AUTOSAR XML (schema 00048)
package /VehicleProject
  system System
package /NM
  nm config NmConfig: can-nm-cluster-coupling=coupled-cluster=[TC37X_VCU_CAN00_CAN, TC37X_VCU_CAN01_CAN, TC37X_VCU_CAN03_CAN]
    can nm cluster TC37X_VCU_CAN00_CAN: communication-cluster=TC37X_VCU_CAN00, nm-channel-id=0, nm-cbv-position=1, nm-msg-cycle-time=0.5, nm-network-timeout=2, nm-repeat-message-time=1.5, nm-user-data-length=6, nm-wait-bus-sleep-time=2
      can nm node GWM: nm-if-ecu=GWM_CAN, nm-node-id=28, rx-nm-pdu=VCU_Tx_51Ch_NM_oTC37X_VCU_CAN00, tx-nm-pdu=VCU_Rx_500h_NM_oTC37X_VCU_CAN00, nm-msg-cycle-offset=0, nm-msg-reduced-time=0.32, nm-range-config={lower-can-id=1024, upper-can-id=1151}
      can nm node Tester: nm-if-ecu=Tester_CAN, nm-node-id=28, nm-passive-mode-enabled=true, nm-msg-cycle-offset=0, nm-msg-reduced-time=0.32, nm-range-config={lower-can-id=1024, upper-can-id=1151}
      can nm node VCU: controller=CT_TC37X_VCU_CAN00, nm-if-ecu=VCU_CAN, nm-node-id=28, rx-nm-pdu=VCU_Rx_500h_NM_oTC37X_VCU_CAN00, tx-nm-pdu=VCU_Tx_51Ch_NM_oTC37X_VCU_CAN00, nm-msg-cycle-offset=0, nm-msg-reduced-time=0.32, nm-range-config={lower-can-id=1024, upper-can-id=1151}
    can nm cluster TC37X_VCU_CAN01_CAN: communication-cluster=TC37X_VCU_CAN01, nm-channel-id=1, nm-cbv-position=1, nm-msg-cycle-time=0.5, nm-network-timeout=2, nm-repeat-message-time=1.5, nm-user-data-length=6, nm-wait-bus-sleep-time=2
      can nm node GWM: nm-if-ecu=GWM_CAN, nm-node-id=28, rx-nm-pdu=VCU_Tx_51Ch_NM_oTC37X_VCU_CAN01, tx-nm-pdu=VCU_Rx_500h_NM_oTC37X_VCU_CAN01, nm-msg-cycle-offset=0, nm-msg-reduced-time=0.32, nm-range-config={lower-can-id=1024, upper-can-id=1151}
      can nm node Tester: nm-if-ecu=Tester_CAN, nm-node-id=28, nm-passive-mode-enabled=true, nm-msg-cycle-offset=0, nm-msg-reduced-time=0.32, nm-range-config={lower-can-id=1024, upper-can-id=1151}
      can nm node VCU: controller=CT_TC37X_VCU_CAN01, nm-if-ecu=VCU_CAN, nm-node-id=28, rx-nm-pdu=VCU_Rx_500h_NM_oTC37X_VCU_CAN01, tx-nm-pdu=VCU_Tx_51Ch_NM_oTC37X_VCU_CAN01, nm-msg-cycle-offset=0, nm-msg-reduced-time=0.32, nm-range-config={lower-can-id=1024, upper-can-id=1151}
    can nm cluster TC37X_VCU_CAN03_CAN: communication-cluster=TC37X_VCU_CAN03, nm-channel-id=2, nm-cbv-position=1, nm-msg-cycle-time=0.5, nm-network-timeout=2, nm-repeat-message-time=1.5, nm-user-data-length=6, nm-wait-bus-sleep-time=2
      can nm node GWM: nm-if-ecu=GWM_CAN, nm-node-id=28, rx-nm-pdu=VCU_Tx_51Ch_NM_oTC37X_VCU_CAN03, tx-nm-pdu=VCU_Rx_500h_NM_oTC37X_VCU_CAN03, nm-msg-cycle-offset=0, nm-msg-reduced-time=0.32, nm-range-config={lower-can-id=1024, upper-can-id=1151}
      can nm node Tester: nm-if-ecu=Tester_CAN, nm-node-id=28, nm-passive-mode-enabled=true, nm-msg-cycle-offset=0, nm-msg-reduced-time=0.32, nm-range-config={lower-can-id=1024, upper-can-id=1151}
      can nm node VCU: controller=CT_TC37X_VCU_CAN03, nm-if-ecu=VCU_CAN, nm-node-id=28, rx-nm-pdu=VCU_Rx_500h_NM_oTC37X_VCU_CAN03, tx-nm-pdu=VCU_Tx_51Ch_NM_oTC37X_VCU_CAN03, nm-msg-cycle-offset=0, nm-msg-reduced-time=0.32, nm-range-config={lower-can-id=1024, upper-can-id=1151}
    nm-if-ecus:
      nm ecu GWM_CAN: nm-node-id-enabled=true, nm-user-data-enabled=true
      nm ecu Tester_CAN: nm-node-id-enabled=true, nm-passive-mode-enabled=true, nm-user-data-enabled=true
      nm ecu VCU_CAN: ecu-instance=VCU, nm-node-id-enabled=true, nm-user-data-enabled=true
package /TP
  can tp config TC37X_VCU_CAN00_CAN: communication-cluster=TC37X_VCU_CAN00, can-tp-ecu{cycle-time-main-function=0.005, ecu-instance=VCU}
    can tp channel TPCH: channel-id=0, channel-mode=FULL-DUPLEX-MODE
    can-tp-connection addressing-format=STANDARD, can-tp-channel=TPCH, data-pdu=Vcu_Uds_Func_Request_Tp_oTC37X_VCU_CAN00, receiver=TN_VCU, ta-type=FUNCTIONAL, tp-sdu=Vcu_Uds_Func_Request_oTC37X_VCU_CAN00, transmitter=TN_Tester:
      ident Vcu_Uds_Func_Request_oTN_Tester
    can-tp-connection addressing-format=STANDARD, can-tp-channel=TPCH, data-pdu=Vcu_Uds_Phy_Request_Tp_oTC37X_VCU_CAN00, flow-control-pdu=Vcu_Uds_Response_Tp_oTC37X_VCU_CAN00, receiver=TN_VCU, ta-type=PHYSICAL, tp-sdu=Vcu_Uds_Phy_Request_oTC37X_VCU_CAN00, transmitter=TN_Tester:
      ident Vcu_Uds_Phy_Request_oTN_VCU
    can-tp-connection addressing-format=STANDARD, can-tp-channel=TPCH, data-pdu=Vcu_Uds_Response_Tp_oTC37X_VCU_CAN00, flow-control-pdu=Vcu_Uds_Phy_Request_Tp_oTC37X_VCU_CAN00, receiver=TN_Tester, ta-type=PHYSICAL, tp-sdu=Vcu_Uds_Response_oTC37X_VCU_CAN00, transmitter=TN_VCU:
      ident Vcu_Uds_Response_oTN_VCU
    can tp node TN_Tester
    can tp node TN_VCU: connector=CN_TC37X_VCU_CAN00
  lin tp config LIN00: communication-cluster=LIN00
    8 x tp address:
      TA_0x005B: tp-address=91
      TA_0x0062: tp-address=98
      TA_0x0063: tp-address=99
      TA_0x0064: tp-address=100
      TA_0x0065: tp-address=101
      TA_0x0074: tp-address=116
      TA_0x0075: tp-address=117
      TA_0x007E: tp-address=126
    tp-connections:
      data-pdu=MasterReq_Tp_oLIN00, lin-tp-n-sdu=MasterReq_oLIN00, multicast=TA_0x007E, receiver=[TN_0x005B_HVCH, TN_0x0062_ERV, TN_0x0063_EXV_1, TN_0x0064_EXV_2, TN_0x0065_SVA, TN_0x0074_PMP_1, TN_0x0075_PMP_2], transmitter=TN_Master
      data-pdu=SlaveResp_Tp_oLIN00, flow-control=MasterReq_Tp_oLIN00, lin-tp-n-sdu=SlaveResp_HVCH_oLIN00, receiver=TN_Master, transmitter=TN_0x005B_HVCH
      data-pdu=SlaveResp_Tp_oLIN00, flow-control=MasterReq_Tp_oLIN00, lin-tp-n-sdu=SlaveResp_ERV_oLIN00, receiver=TN_Master, transmitter=TN_0x0062_ERV
      data-pdu=SlaveResp_Tp_oLIN00, flow-control=MasterReq_Tp_oLIN00, lin-tp-n-sdu=SlaveResp_EXV_1_oLIN00, receiver=TN_Master, transmitter=TN_0x0063_EXV_1
      data-pdu=SlaveResp_Tp_oLIN00, flow-control=MasterReq_Tp_oLIN00, lin-tp-n-sdu=SlaveResp_EXV_2_oLIN00, receiver=TN_Master, transmitter=TN_0x0064_EXV_2
      data-pdu=SlaveResp_Tp_oLIN00, flow-control=MasterReq_Tp_oLIN00, lin-tp-n-sdu=SlaveResp_SVA_oLIN00, receiver=TN_Master, transmitter=TN_0x0065_SVA
      data-pdu=SlaveResp_Tp_oLIN00, flow-control=MasterReq_Tp_oLIN00, lin-tp-n-sdu=SlaveResp_PMP_1_oLIN00, receiver=TN_Master, transmitter=TN_0x0074_PMP_1
      data-pdu=SlaveResp_Tp_oLIN00, flow-control=MasterReq_Tp_oLIN00, lin-tp-n-sdu=SlaveResp_PMP_2_oLIN00, receiver=TN_Master, transmitter=TN_0x0075_PMP_2
      data-pdu=MasterReq_Tp_oLIN00, flow-control=SlaveResp_Tp_oLIN00, lin-tp-n-sdu=MasterReq_HVCH_oLIN00, receiver=TN_0x005B_HVCH, transmitter=TN_Master
      data-pdu=MasterReq_Tp_oLIN00, flow-control=SlaveResp_Tp_oLIN00, lin-tp-n-sdu=MasterReq_ERV_oLIN00, receiver=TN_0x0062_ERV, transmitter=TN_Master
      data-pdu=MasterReq_Tp_oLIN00, flow-control=SlaveResp_Tp_oLIN00, lin-tp-n-sdu=MasterReq_EXV_1_oLIN00, receiver=TN_0x0063_EXV_1, transmitter=TN_Master
      data-pdu=MasterReq_Tp_oLIN00, flow-control=SlaveResp_Tp_oLIN00, lin-tp-n-sdu=MasterReq_EXV_2_oLIN00, receiver=TN_0x0064_EXV_2, transmitter=TN_Master
      data-pdu=MasterReq_Tp_oLIN00, flow-control=SlaveResp_Tp_oLIN00, lin-tp-n-sdu=MasterReq_SVA_oLIN00, receiver=TN_0x0065_SVA, transmitter=TN_Master
      data-pdu=MasterReq_Tp_oLIN00, flow-control=SlaveResp_Tp_oLIN00, lin-tp-n-sdu=MasterReq_PMP_1_oLIN00, receiver=TN_0x0074_PMP_1, transmitter=TN_Master
      data-pdu=MasterReq_Tp_oLIN00, flow-control=SlaveResp_Tp_oLIN00, lin-tp-n-sdu=MasterReq_PMP_2_oLIN00, receiver=TN_0x0075_PMP_2, transmitter=TN_Master
    8 x lin tp node:
      TN_0x005B_HVCH: tp-address=TA_0x005B
      TN_0x0062_ERV: tp-address=TA_0x0062
      TN_0x0063_EXV_1: tp-address=TA_0x0063
      TN_0x0064_EXV_2: tp-address=TA_0x0064
      TN_0x0065_SVA: tp-address=TA_0x0065
      TN_0x0074_PMP_1: tp-address=TA_0x0074
      TN_0x0075_PMP_2: tp-address=TA_0x0075
      TN_Master: connector=CN_LIN00
package /Cluster
  4 x can cluster, all with baudrate=500000, protocol-name=CAN:
    KAMA_FP_EPT_0303
      can physical channel CHNL: comm-connectors=CN_KAMA_FP_EPT_0303
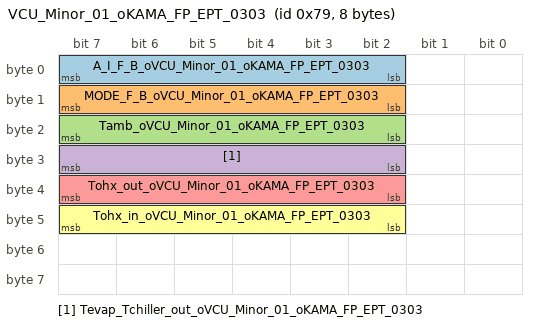
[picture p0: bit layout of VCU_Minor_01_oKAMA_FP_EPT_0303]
        frame VCU_Minor_01_oKAMA_FP_EPT_0303: id 0x79, from VCU, frame-length=8, can-addressing-mode=STANDARD
          pdu VCU_Minor_01_oKAMA_FP_EPT_0303: length=8, minimum-delay=0, transmission-mode-false-timing=cyclic-timing={time-offset=0, time-period=0.02}, transmission-mode-true-timing=cyclic-timing={time-offset=0, time-period=0.02}, unused-bit-pattern=0
            signal A_I_F_B_oVCU_Minor_01_oKAMA_FP_EPT_0303: start 7, 6 bit, big-endian, i-signal-type=PRIMITIVE, init-value=0, base-type=uint8, compu-method=CM_A_I_F_B, data-constr=DC_A_I_F_B, unit=U_V, transfer-property=PENDING
            signal MODE_F_B_oVCU_Minor_01_oKAMA_FP_EPT_0303: start 15, 6 bit, big-endian, i-signal-type=PRIMITIVE, init-value=0, base-type=uint8, compu-method=CM_MODE_F_B, data-constr=DC_MODE_F_B, unit=U_V, transfer-property=PENDING
            signal Tamb_oVCU_Minor_01_oKAMA_FP_EPT_0303: start 23, 6 bit, big-endian, i-signal-type=PRIMITIVE, init-value=0, base-type=uint8, compu-method=CM_Tamb, data-constr=DC_Tamb, unit=U_V, transfer-property=PENDING
            signal Tevap_Tchiller_out_oVCU_Minor_01_oKAMA_FP_EPT_0303: start 31, 6 bit, big-endian, i-signal-type=PRIMITIVE, init-value=0, base-type=uint8, compu-method=CM_Tevap_Tchiller_out, data-constr=DC_Tevap_Tchiller_out, unit=U_V, transfer-property=PENDING
            signal Tohx_out_oVCU_Minor_01_oKAMA_FP_EPT_0303: start 39, 6 bit, big-endian, i-signal-type=PRIMITIVE, init-value=0, base-type=uint8, compu-method=CM_Tohx_out, data-constr=DC_Tohx_out, unit=U_V, transfer-property=PENDING
            signal Tohx_in_oVCU_Minor_01_oKAMA_FP_EPT_0303: start 47, 6 bit, big-endian, i-signal-type=PRIMITIVE, init-value=0, base-type=uint8, compu-method=CM_Tohx_in, data-constr=DC_Tohx_in, unit=U_V, transfer-property=PENDING
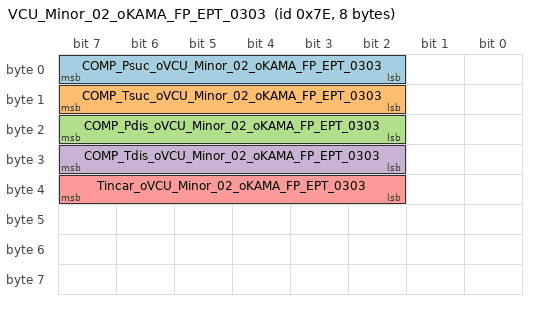
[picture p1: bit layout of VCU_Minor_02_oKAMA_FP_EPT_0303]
        frame VCU_Minor_02_oKAMA_FP_EPT_0303: id 0x7E, from VCU, frame-length=8, can-addressing-mode=STANDARD
          pdu VCU_Minor_02_oKAMA_FP_EPT_0303: length=8, minimum-delay=0, transmission-mode-false-timing=cyclic-timing={time-offset=0, time-period=0.02}, transmission-mode-true-timing=cyclic-timing={time-offset=0, time-period=0.02}, unused-bit-pattern=0
            signal COMP_Psuc_oVCU_Minor_02_oKAMA_FP_EPT_0303: start 7, 6 bit, big-endian, i-signal-type=PRIMITIVE, init-value=0, base-type=uint8, compu-method=CM_COMP_Psuc, data-constr=DC_COMP_Psuc, unit=U_V, transfer-property=PENDING
            signal COMP_Tsuc_oVCU_Minor_02_oKAMA_FP_EPT_0303: start 15, 6 bit, big-endian, i-signal-type=PRIMITIVE, init-value=0, base-type=uint8, compu-method=CM_COMP_Tsuc, data-constr=DC_COMP_Tsuc, unit=U_V, transfer-property=PENDING
            signal COMP_Pdis_oVCU_Minor_02_oKAMA_FP_EPT_0303: start 23, 6 bit, big-endian, i-signal-type=PRIMITIVE, init-value=0, base-type=uint8, compu-method=CM_COMP_Pdis, data-constr=DC_COMP_Pdis, unit=U_V, transfer-property=PENDING
            signal COMP_Tdis_oVCU_Minor_02_oKAMA_FP_EPT_0303: start 31, 6 bit, big-endian, i-signal-type=PRIMITIVE, init-value=0, base-type=uint8, compu-method=CM_COMP_Tdis, data-constr=DC_COMP_Tdis, unit=U_V, transfer-property=PENDING
            signal Tincar_oVCU_Minor_02_oKAMA_FP_EPT_0303: start 39, 6 bit, big-endian, i-signal-type=PRIMITIVE, init-value=0, base-type=uint8, compu-method=CM_Tincar, data-constr=DC_Tincar, unit=U_V, transfer-property=PENDING
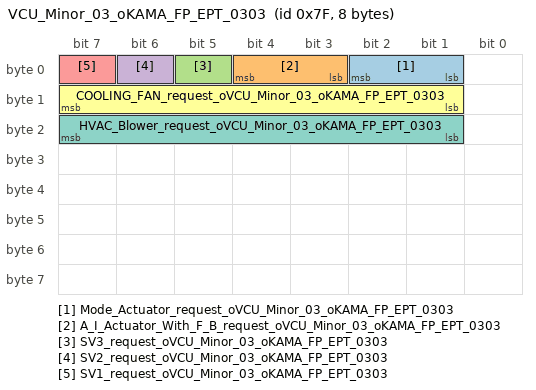
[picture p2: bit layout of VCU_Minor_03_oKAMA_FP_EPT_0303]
        frame VCU_Minor_03_oKAMA_FP_EPT_0303: id 0x7F, to VCU, frame-length=8, can-addressing-mode=STANDARD
          pdu VCU_Minor_03_oKAMA_FP_EPT_0303: length=8, minimum-delay=0, transmission-mode-false-timing=cyclic-timing={time-offset=0, time-period=0.02}, transmission-mode-true-timing=cyclic-timing={time-offset=0, time-period=0.02}, unused-bit-pattern=0
            signal Mode_Actuator_request_oVCU_Minor_03_oKAMA_FP_EPT_0303: start 2, 2 bit, big-endian, i-signal-type=PRIMITIVE, init-value=0, base-type=uint8, compu-method=CM_Mode_Actuator_request, data-constr=DC_Mode_Actuator_request, transfer-property=PENDING, to VCU
            signal A_I_Actuator_With_F_B_request_oVCU_Minor_03_oKAMA_FP_EPT_0303: start 4, 2 bit, big-endian, i-signal-type=PRIMITIVE, init-value=0, base-type=uint8, compu-method=CM_A_I_Actuator_With_F_B_request, data-constr=DC_A_I_Actuator_With_F_B_request, transfer-property=PENDING, to VCU
            signal SV3_request_oVCU_Minor_03_oKAMA_FP_EPT_0303: start 5, 1 bit, big-endian, i-signal-type=PRIMITIVE, init-value=0, base-type=boolean, compu-method=CM_SV3_request, data-constr=DC_SV3_request, transfer-property=PENDING, to VCU
            signal SV2_request_oVCU_Minor_03_oKAMA_FP_EPT_0303: start 6, 1 bit, big-endian, i-signal-type=PRIMITIVE, init-value=0, base-type=boolean, compu-method=CM_SV2_request, data-constr=DC_SV2_request, transfer-property=PENDING, to VCU
            signal SV1_request_oVCU_Minor_03_oKAMA_FP_EPT_0303: start 7, 1 bit, big-endian, i-signal-type=PRIMITIVE, init-value=0, base-type=boolean, compu-method=CM_SV1_request, data-constr=DC_SV1_request, transfer-property=PENDING, to VCU
            signal COOLING_FAN_request_oVCU_Minor_03_oKAMA_FP_EPT_0303: start 15, 7 bit, big-endian, i-signal-type=PRIMITIVE, init-value=0, base-type=uint8, compu-method=CM_COOLING_FAN_request, data-constr=DC_COOLING_FAN_request, unit=U_p, transfer-property=PENDING, to VCU
            signal HVAC_Blower_request_oVCU_Minor_03_oKAMA_FP_EPT_0303: start 23, 7 bit, big-endian, i-signal-type=PRIMITIVE, init-value=0, base-type=uint8, compu-method=CM_HVAC_Blower_request, data-constr=DC_HVAC_Blower_request, unit=U_p, transfer-property=PENDING, to VCU
    TC37X_VCU_CAN00  # VCU_CAN00
      can physical channel CHNL: comm-connectors=CN_TC37X_VCU_CAN00
        frame VCU_Rx_500h_NM_oTC37X_VCU_CAN00: id 0x500, to VCU, frame-length=8, can-addressing-mode=STANDARD
          nm pdu VCU_Rx_500h_NM_oTC37X_VCU_CAN00: length=8, unused-bit-pattern=0
        frame VCU_Tx_51Ch_NM_oTC37X_VCU_CAN00: id 0x51C, from VCU, frame-length=8, can-addressing-mode=STANDARD
          nm pdu VCU_Tx_51Ch_NM_oTC37X_VCU_CAN00: length=8, unused-bit-pattern=0
            signal VCU_Tx_51Ch_NM_PNCData_oVCU_Tx_51Ch_NM_oTC37X_VCU_CAN00: start 16, 48 bit, opaque, i-signal-type=ARRAY, init-value=6 x 0, base-type=uint8_6_none, compu-method=CM_VCU_Tx_51Ch_NM_PNCData, data-constr=DC_VCU_Tx_51Ch_NM_PNCData, transfer-property=PENDING
        frame Vcu_Uds_Func_Request_oTC37X_VCU_CAN00: id 0x700, to VCU, frame-length=8, can-addressing-mode=STANDARD
          n pdu Vcu_Uds_Func_Request_Tp_oTC37X_VCU_CAN00: length=8
        frame Vcu_Uds_Phy_Request_oTC37X_VCU_CAN00: id 0x701, to VCU, frame-length=8, can-addressing-mode=STANDARD
          n pdu Vcu_Uds_Phy_Request_Tp_oTC37X_VCU_CAN00: length=8
        frame Vcu_Uds_Response_oTC37X_VCU_CAN00: id 0x781, from VCU, frame-length=8, can-addressing-mode=STANDARD
          n pdu Vcu_Uds_Response_Tp_oTC37X_VCU_CAN00: length=8
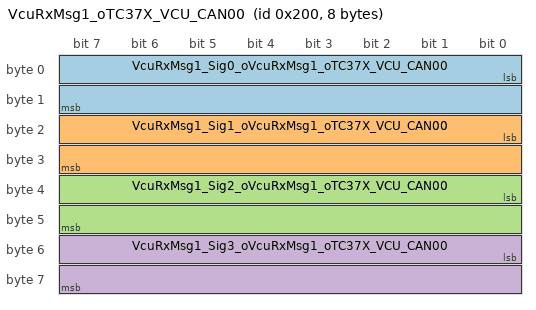
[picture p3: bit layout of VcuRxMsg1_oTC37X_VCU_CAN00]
        frame VcuRxMsg1_oTC37X_VCU_CAN00: id 0x200, to VCU, frame-length=8, can-addressing-mode=STANDARD
          pdu VcuRxMsg1_oTC37X_VCU_CAN00: length=8, minimum-delay=0, transmission-mode-false-timing=cyclic-timing={time-offset=0, time-period=0.5}, transmission-mode-true-timing=cyclic-timing={time-offset=0, time-period=0.5}, unused-bit-pattern=0
            signal VcuRxMsg1_Sig0_oVcuRxMsg1_oTC37X_VCU_CAN00: start 0, 16 bit, little-endian, i-signal-type=PRIMITIVE, init-value=0, base-type=sint16, compu-method=CM_VcuRxMsg1_Sig0, data-constr=DC_VcuRxMsg1_Sig0, transfer-property=PENDING, to VCU
            signal VcuRxMsg1_Sig1_oVcuRxMsg1_oTC37X_VCU_CAN00: start 16, 16 bit, little-endian, i-signal-type=PRIMITIVE, init-value=0, base-type=sint16, compu-method=CM_VcuRxMsg1_Sig1, data-constr=DC_VcuRxMsg1_Sig1, transfer-property=PENDING, to VCU
            signal VcuRxMsg1_Sig2_oVcuRxMsg1_oTC37X_VCU_CAN00: start 32, 16 bit, little-endian, i-signal-type=PRIMITIVE, init-value=0, base-type=sint16, compu-method=CM_VcuRxMsg1_Sig2, data-constr=DC_VcuRxMsg1_Sig2, transfer-property=PENDING, to VCU
            signal VcuRxMsg1_Sig3_oVcuRxMsg1_oTC37X_VCU_CAN00: start 48, 16 bit, little-endian, i-signal-type=PRIMITIVE, init-value=0, base-type=sint16, compu-method=CM_VcuRxMsg1_Sig3, data-constr=DC_VcuRxMsg1_Sig3, transfer-property=PENDING, to VCU
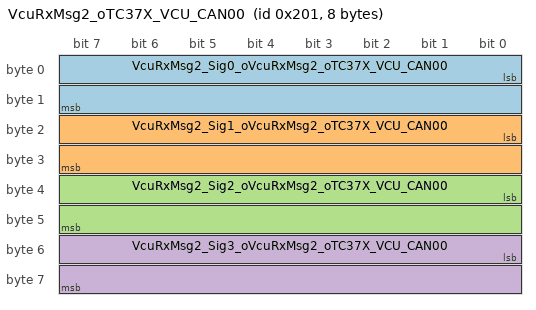
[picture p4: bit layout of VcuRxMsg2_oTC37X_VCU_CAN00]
        frame VcuRxMsg2_oTC37X_VCU_CAN00: id 0x201, to VCU, frame-length=8, can-addressing-mode=STANDARD
          pdu VcuRxMsg2_oTC37X_VCU_CAN00: length=8, minimum-delay=0, transmission-mode-false-timing=cyclic-timing={time-offset=0, time-period=0.5}, transmission-mode-true-timing=cyclic-timing={time-offset=0, time-period=0.5}, unused-bit-pattern=0
            signal VcuRxMsg2_Sig0_oVcuRxMsg2_oTC37X_VCU_CAN00: start 0, 16 bit, little-endian, i-signal-type=PRIMITIVE, init-value=0, base-type=sint16, compu-method=CM_VcuRxMsg2_Sig0, data-constr=DC_VcuRxMsg2_Sig0, transfer-property=PENDING, to VCU
            signal VcuRxMsg2_Sig1_oVcuRxMsg2_oTC37X_VCU_CAN00: start 16, 16 bit, little-endian, i-signal-type=PRIMITIVE, init-value=0, base-type=sint16, compu-method=CM_VcuRxMsg2_Sig1, data-constr=DC_VcuRxMsg2_Sig1, transfer-property=PENDING, to VCU
            signal VcuRxMsg2_Sig2_oVcuRxMsg2_oTC37X_VCU_CAN00: start 32, 16 bit, little-endian, i-signal-type=PRIMITIVE, init-value=0, base-type=sint16, compu-method=CM_VcuRxMsg2_Sig2, data-constr=DC_VcuRxMsg2_Sig2, transfer-property=PENDING, to VCU
            signal VcuRxMsg2_Sig3_oVcuRxMsg2_oTC37X_VCU_CAN00: start 48, 16 bit, little-endian, i-signal-type=PRIMITIVE, init-value=0, base-type=sint16, compu-method=CM_VcuRxMsg2_Sig3, data-constr=DC_VcuRxMsg2_Sig3, transfer-property=PENDING, to VCU
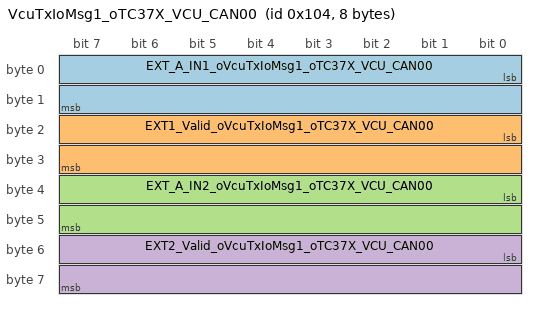
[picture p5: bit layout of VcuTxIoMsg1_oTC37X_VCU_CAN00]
        frame VcuTxIoMsg1_oTC37X_VCU_CAN00: id 0x104, from VCU, frame-length=8, can-addressing-mode=STANDARD
          pdu VcuTxIoMsg1_oTC37X_VCU_CAN00: length=8, minimum-delay=0, transmission-mode-false-timing=cyclic-timing={time-offset=0, time-period=0.5}, transmission-mode-true-timing=cyclic-timing={time-offset=0, time-period=0.5}, unused-bit-pattern=0
            signal EXT_A_IN1_oVcuTxIoMsg1_oTC37X_VCU_CAN00: start 0, 16 bit, little-endian, i-signal-type=PRIMITIVE, init-value=0, base-type=sint16, compu-method=CM_EXT_A_IN1, data-constr=DC_EXT_A_IN1, unit=U_C, transfer-property=PENDING
            signal EXT1_Valid_oVcuTxIoMsg1_oTC37X_VCU_CAN00: start 16, 16 bit, little-endian, i-signal-type=PRIMITIVE, init-value=0, base-type=uint16, compu-method=CM_EXT1_Valid, data-constr=DC_EXT1_Valid, transfer-property=PENDING
            signal EXT_A_IN2_oVcuTxIoMsg1_oTC37X_VCU_CAN00: start 32, 16 bit, little-endian, i-signal-type=PRIMITIVE, init-value=0, base-type=sint16, compu-method=CM_EXT_A_IN2, data-constr=DC_EXT_A_IN2, unit=U_C, transfer-property=PENDING
            signal EXT2_Valid_oVcuTxIoMsg1_oTC37X_VCU_CAN00: start 48, 16 bit, little-endian, i-signal-type=PRIMITIVE, init-value=0, base-type=uint16, compu-method=CM_EXT2_Valid, data-constr=DC_EXT2_Valid, transfer-property=PENDING
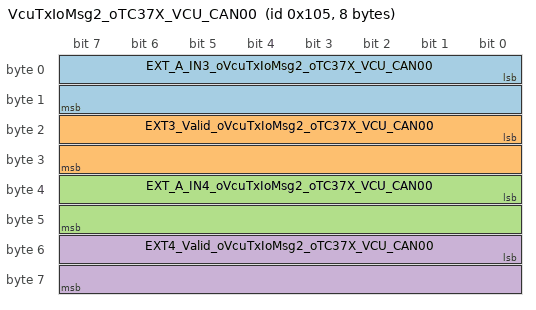
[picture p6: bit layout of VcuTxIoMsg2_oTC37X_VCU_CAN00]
        frame VcuTxIoMsg2_oTC37X_VCU_CAN00: id 0x105, from VCU, frame-length=8, can-addressing-mode=STANDARD
          pdu VcuTxIoMsg2_oTC37X_VCU_CAN00: length=8, minimum-delay=0, transmission-mode-false-timing=cyclic-timing={time-offset=0, time-period=0.5}, transmission-mode-true-timing=cyclic-timing={time-offset=0, time-period=0.5}, unused-bit-pattern=0
            signal EXT_A_IN3_oVcuTxIoMsg2_oTC37X_VCU_CAN00: start 0, 16 bit, little-endian, i-signal-type=PRIMITIVE, init-value=0, base-type=sint16, compu-method=CM_EXT_A_IN3, data-constr=DC_EXT_A_IN3, unit=U_C, transfer-property=PENDING
            signal EXT3_Valid_oVcuTxIoMsg2_oTC37X_VCU_CAN00: start 16, 16 bit, little-endian, i-signal-type=PRIMITIVE, init-value=0, base-type=uint16, compu-method=CM_EXT3_Valid, data-constr=DC_EXT3_Valid, transfer-property=PENDING
            signal EXT_A_IN4_oVcuTxIoMsg2_oTC37X_VCU_CAN00: start 32, 16 bit, little-endian, i-signal-type=PRIMITIVE, init-value=0, base-type=sint16, compu-method=CM_EXT_A_IN4, data-constr=DC_EXT_A_IN4, unit=U_C, transfer-property=PENDING
            signal EXT4_Valid_oVcuTxIoMsg2_oTC37X_VCU_CAN00: start 48, 16 bit, little-endian, i-signal-type=PRIMITIVE, init-value=0, base-type=uint16, compu-method=CM_EXT4_Valid, data-constr=DC_EXT4_Valid, transfer-property=PENDING
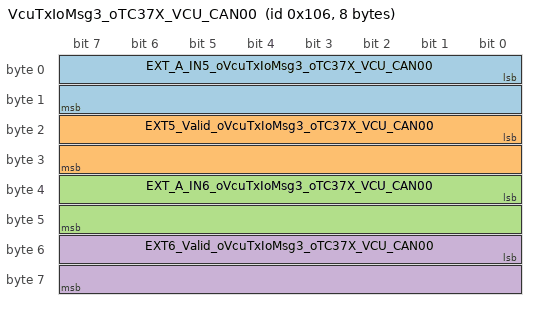
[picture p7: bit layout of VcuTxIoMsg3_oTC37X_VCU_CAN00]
        frame VcuTxIoMsg3_oTC37X_VCU_CAN00: id 0x106, from VCU, frame-length=8, can-addressing-mode=STANDARD
          pdu VcuTxIoMsg3_oTC37X_VCU_CAN00: length=8, minimum-delay=0, transmission-mode-false-timing=cyclic-timing={time-offset=0, time-period=0.5}, transmission-mode-true-timing=cyclic-timing={time-offset=0, time-period=0.5}, unused-bit-pattern=0
            signal EXT_A_IN5_oVcuTxIoMsg3_oTC37X_VCU_CAN00: start 0, 16 bit, little-endian, i-signal-type=PRIMITIVE, init-value=0, base-type=sint16, compu-method=CM_EXT_A_IN5, data-constr=DC_EXT_A_IN5, unit=U_C, transfer-property=PENDING
            signal EXT5_Valid_oVcuTxIoMsg3_oTC37X_VCU_CAN00: start 16, 16 bit, little-endian, i-signal-type=PRIMITIVE, init-value=0, base-type=uint16, compu-method=CM_EXT5_Valid, data-constr=DC_EXT5_Valid, transfer-property=PENDING
            signal EXT_A_IN6_oVcuTxIoMsg3_oTC37X_VCU_CAN00: start 32, 16 bit, little-endian, i-signal-type=PRIMITIVE, init-value=0, base-type=sint16, compu-method=CM_EXT_A_IN6, data-constr=DC_EXT_A_IN6, unit=U_C, transfer-property=PENDING
            signal EXT6_Valid_oVcuTxIoMsg3_oTC37X_VCU_CAN00: start 48, 16 bit, little-endian, i-signal-type=PRIMITIVE, init-value=0, base-type=uint16, compu-method=CM_EXT6_Valid, data-constr=DC_EXT6_Valid, transfer-property=PENDING
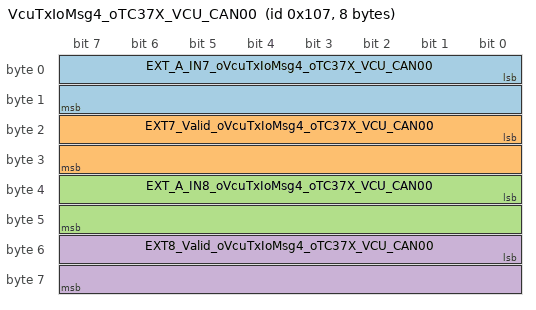
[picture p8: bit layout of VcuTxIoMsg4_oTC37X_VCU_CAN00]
        frame VcuTxIoMsg4_oTC37X_VCU_CAN00: id 0x107, from VCU, frame-length=8, can-addressing-mode=STANDARD
          pdu VcuTxIoMsg4_oTC37X_VCU_CAN00: length=8, minimum-delay=0, transmission-mode-false-timing=cyclic-timing={time-offset=0, time-period=0.5}, transmission-mode-true-timing=cyclic-timing={time-offset=0, time-period=0.5}, unused-bit-pattern=0
            signal EXT_A_IN7_oVcuTxIoMsg4_oTC37X_VCU_CAN00: start 0, 16 bit, little-endian, i-signal-type=PRIMITIVE, init-value=0, base-type=sint16, compu-method=CM_EXT_A_IN7, data-constr=DC_EXT_A_IN7, unit=U_C, transfer-property=PENDING
            signal EXT7_Valid_oVcuTxIoMsg4_oTC37X_VCU_CAN00: start 16, 16 bit, little-endian, i-signal-type=PRIMITIVE, init-value=0, base-type=uint16, compu-method=CM_EXT7_Valid, data-constr=DC_EXT7_Valid, transfer-property=PENDING
            signal EXT_A_IN8_oVcuTxIoMsg4_oTC37X_VCU_CAN00: start 32, 16 bit, little-endian, i-signal-type=PRIMITIVE, init-value=0, base-type=sint16, compu-method=CM_EXT_A_IN8, data-constr=DC_EXT_A_IN8, unit=U_C, transfer-property=PENDING
            signal EXT8_Valid_oVcuTxIoMsg4_oTC37X_VCU_CAN00: start 48, 16 bit, little-endian, i-signal-type=PRIMITIVE, init-value=0, base-type=uint16, compu-method=CM_EXT8_Valid, data-constr=DC_EXT8_Valid, transfer-property=PENDING
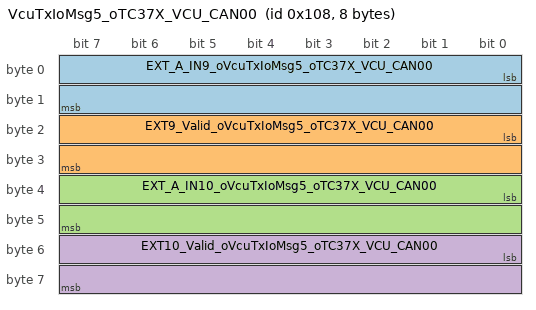
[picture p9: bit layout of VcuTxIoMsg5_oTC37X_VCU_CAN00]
        frame VcuTxIoMsg5_oTC37X_VCU_CAN00: id 0x108, from VCU, frame-length=8, can-addressing-mode=STANDARD
          pdu VcuTxIoMsg5_oTC37X_VCU_CAN00: length=8, minimum-delay=0, transmission-mode-false-timing=cyclic-timing={time-offset=0, time-period=0.5}, transmission-mode-true-timing=cyclic-timing={time-offset=0, time-period=0.5}, unused-bit-pattern=0
            signal EXT_A_IN9_oVcuTxIoMsg5_oTC37X_VCU_CAN00: start 0, 16 bit, little-endian, i-signal-type=PRIMITIVE, init-value=0, base-type=sint16, compu-method=CM_EXT_A_IN9, data-constr=DC_EXT_A_IN9, unit=U_C, transfer-property=PENDING
            signal EXT9_Valid_oVcuTxIoMsg5_oTC37X_VCU_CAN00: start 16, 16 bit, little-endian, i-signal-type=PRIMITIVE, init-value=0, base-type=uint16, compu-method=CM_EXT9_Valid, data-constr=DC_EXT9_Valid, transfer-property=PENDING
            signal EXT_A_IN10_oVcuTxIoMsg5_oTC37X_VCU_CAN00: start 32, 16 bit, little-endian, i-signal-type=PRIMITIVE, init-value=0, base-type=sint16, compu-method=CM_EXT_A_IN10, data-constr=DC_EXT_A_IN10, unit=U_C, transfer-property=PENDING
            signal EXT10_Valid_oVcuTxIoMsg5_oTC37X_VCU_CAN00: start 48, 16 bit, little-endian, i-signal-type=PRIMITIVE, init-value=0, base-type=uint16, compu-method=CM_EXT10_Valid, data-constr=DC_EXT10_Valid, transfer-property=PENDING
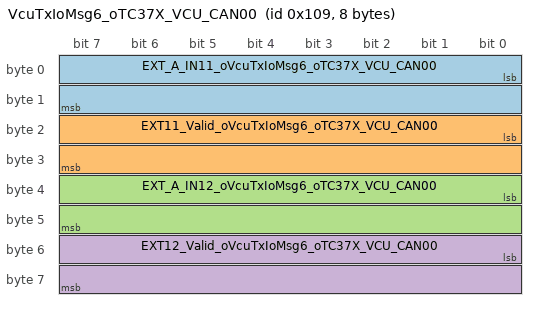
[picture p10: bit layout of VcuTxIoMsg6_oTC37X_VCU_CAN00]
        frame VcuTxIoMsg6_oTC37X_VCU_CAN00: id 0x109, from VCU, frame-length=8, can-addressing-mode=STANDARD
          pdu VcuTxIoMsg6_oTC37X_VCU_CAN00: length=8, minimum-delay=0, transmission-mode-false-timing=cyclic-timing={time-offset=0, time-period=0.5}, transmission-mode-true-timing=cyclic-timing={time-offset=0, time-period=0.5}, unused-bit-pattern=0
            signal EXT_A_IN11_oVcuTxIoMsg6_oTC37X_VCU_CAN00: start 0, 16 bit, little-endian, i-signal-type=PRIMITIVE, init-value=0, base-type=sint16, compu-method=CM_EXT_A_IN11, data-constr=DC_EXT_A_IN11, unit=U_C, transfer-property=PENDING
            signal EXT11_Valid_oVcuTxIoMsg6_oTC37X_VCU_CAN00: start 16, 16 bit, little-endian, i-signal-type=PRIMITIVE, init-value=0, base-type=uint16, compu-method=CM_EXT11_Valid, data-constr=DC_EXT11_Valid, transfer-property=PENDING
            signal EXT_A_IN12_oVcuTxIoMsg6_oTC37X_VCU_CAN00: start 32, 16 bit, little-endian, i-signal-type=PRIMITIVE, init-value=0, base-type=sint16, compu-method=CM_EXT_A_IN12, data-constr=DC_EXT_A_IN12, unit=U_C, transfer-property=PENDING
            signal EXT12_Valid_oVcuTxIoMsg6_oTC37X_VCU_CAN00: start 48, 16 bit, little-endian, i-signal-type=PRIMITIVE, init-value=0, base-type=uint16, compu-method=CM_EXT12_Valid, data-constr=DC_EXT12_Valid, transfer-property=PENDING
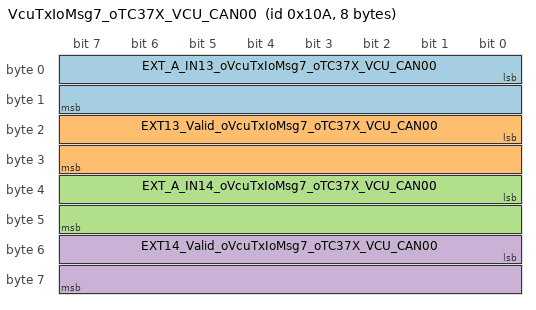
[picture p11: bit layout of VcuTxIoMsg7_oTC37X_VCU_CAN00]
        frame VcuTxIoMsg7_oTC37X_VCU_CAN00: id 0x10A, from VCU, frame-length=8, can-addressing-mode=STANDARD
          pdu VcuTxIoMsg7_oTC37X_VCU_CAN00: length=8, minimum-delay=0, transmission-mode-false-timing=cyclic-timing={time-offset=0, time-period=0.5}, transmission-mode-true-timing=cyclic-timing={time-offset=0, time-period=0.5}, unused-bit-pattern=0
            signal EXT_A_IN13_oVcuTxIoMsg7_oTC37X_VCU_CAN00: start 0, 16 bit, little-endian, i-signal-type=PRIMITIVE, init-value=0, base-type=sint16, compu-method=CM_EXT_A_IN13, data-constr=DC_EXT_A_IN13, unit=U_C, transfer-property=PENDING
            signal EXT13_Valid_oVcuTxIoMsg7_oTC37X_VCU_CAN00: start 16, 16 bit, little-endian, i-signal-type=PRIMITIVE, init-value=0, base-type=uint16, compu-method=CM_EXT13_Valid, data-constr=DC_EXT13_Valid, transfer-property=PENDING
            signal EXT_A_IN14_oVcuTxIoMsg7_oTC37X_VCU_CAN00: start 32, 16 bit, little-endian, i-signal-type=PRIMITIVE, init-value=0, base-type=sint16, compu-method=CM_EXT_A_IN14, data-constr=DC_EXT_A_IN14, unit=U_C, transfer-property=PENDING
            signal EXT14_Valid_oVcuTxIoMsg7_oTC37X_VCU_CAN00: start 48, 16 bit, little-endian, i-signal-type=PRIMITIVE, init-value=0, base-type=uint16, compu-method=CM_EXT14_Valid, data-constr=DC_EXT14_Valid, transfer-property=PENDING
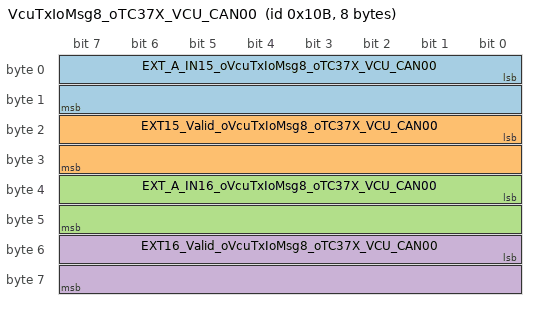
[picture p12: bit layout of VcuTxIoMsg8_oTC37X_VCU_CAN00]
        frame VcuTxIoMsg8_oTC37X_VCU_CAN00: id 0x10B, from VCU, frame-length=8, can-addressing-mode=STANDARD
          pdu VcuTxIoMsg8_oTC37X_VCU_CAN00: length=8, minimum-delay=0, transmission-mode-false-timing=cyclic-timing={time-offset=0, time-period=0.5}, transmission-mode-true-timing=cyclic-timing={time-offset=0, time-period=0.5}, unused-bit-pattern=0
            signal EXT_A_IN15_oVcuTxIoMsg8_oTC37X_VCU_CAN00: start 0, 16 bit, little-endian, i-signal-type=PRIMITIVE, init-value=0, base-type=sint16, compu-method=CM_EXT_A_IN15, data-constr=DC_EXT_A_IN15, unit=U_C, transfer-property=PENDING
            signal EXT15_Valid_oVcuTxIoMsg8_oTC37X_VCU_CAN00: start 16, 16 bit, little-endian, i-signal-type=PRIMITIVE, init-value=0, base-type=uint16, compu-method=CM_EXT15_Valid, data-constr=DC_EXT15_Valid, transfer-property=PENDING
            signal EXT_A_IN16_oVcuTxIoMsg8_oTC37X_VCU_CAN00: start 32, 16 bit, little-endian, i-signal-type=PRIMITIVE, init-value=0, base-type=sint16, compu-method=CM_EXT_A_IN16, data-constr=DC_EXT_A_IN16, unit=U_C, transfer-property=PENDING
            signal EXT16_Valid_oVcuTxIoMsg8_oTC37X_VCU_CAN00: start 48, 16 bit, little-endian, i-signal-type=PRIMITIVE, init-value=0, base-type=uint16, compu-method=CM_EXT16_Valid, data-constr=DC_EXT16_Valid, transfer-property=PENDING
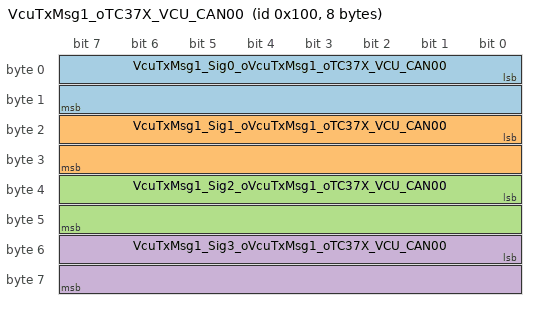
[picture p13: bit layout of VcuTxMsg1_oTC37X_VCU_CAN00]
        frame VcuTxMsg1_oTC37X_VCU_CAN00: id 0x100, from VCU, frame-length=8, can-addressing-mode=STANDARD
          pdu VcuTxMsg1_oTC37X_VCU_CAN00: length=8, minimum-delay=0, transmission-mode-false-timing=cyclic-timing={time-offset=0, time-period=0.5}, transmission-mode-true-timing=cyclic-timing={time-offset=0, time-period=0.5}, unused-bit-pattern=0
            signal VcuTxMsg1_Sig0_oVcuTxMsg1_oTC37X_VCU_CAN00: start 0, 16 bit, little-endian, i-signal-type=PRIMITIVE, init-value=0, base-type=sint16, compu-method=CM_VcuTxMsg1_Sig0, data-constr=DC_VcuTxMsg1_Sig0, transfer-property=PENDING
            signal VcuTxMsg1_Sig1_oVcuTxMsg1_oTC37X_VCU_CAN00: start 16, 16 bit, little-endian, i-signal-type=PRIMITIVE, init-value=0, base-type=sint16, compu-method=CM_VcuTxMsg1_Sig1, data-constr=DC_VcuTxMsg1_Sig1, transfer-property=PENDING
            signal VcuTxMsg1_Sig2_oVcuTxMsg1_oTC37X_VCU_CAN00: start 32, 16 bit, little-endian, i-signal-type=PRIMITIVE, init-value=0, base-type=sint16, compu-method=CM_VcuTxMsg1_Sig2, data-constr=DC_VcuTxMsg1_Sig2, transfer-property=PENDING
            signal VcuTxMsg1_Sig3_oVcuTxMsg1_oTC37X_VCU_CAN00: start 48, 16 bit, little-endian, i-signal-type=PRIMITIVE, init-value=0, base-type=sint16, compu-method=CM_VcuTxMsg1_Sig3, data-constr=DC_VcuTxMsg1_Sig3, transfer-property=PENDING
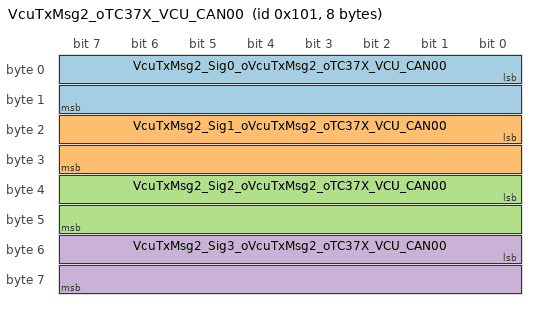
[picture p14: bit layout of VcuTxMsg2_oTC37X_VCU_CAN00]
        frame VcuTxMsg2_oTC37X_VCU_CAN00: id 0x101, from VCU, frame-length=8, can-addressing-mode=STANDARD
          pdu VcuTxMsg2_oTC37X_VCU_CAN00: length=8, minimum-delay=0, transmission-mode-false-timing=cyclic-timing={time-offset=0, time-period=0.5}, transmission-mode-true-timing=cyclic-timing={time-offset=0, time-period=0.5}, unused-bit-pattern=0
            signal VcuTxMsg2_Sig0_oVcuTxMsg2_oTC37X_VCU_CAN00: start 0, 16 bit, little-endian, i-signal-type=PRIMITIVE, init-value=0, base-type=sint16, compu-method=CM_VcuTxMsg2_Sig0, data-constr=DC_VcuTxMsg2_Sig0, transfer-property=PENDING
            signal VcuTxMsg2_Sig1_oVcuTxMsg2_oTC37X_VCU_CAN00: start 16, 16 bit, little-endian, i-signal-type=PRIMITIVE, init-value=0, base-type=sint16, compu-method=CM_VcuTxMsg2_Sig1, data-constr=DC_VcuTxMsg2_Sig1, transfer-property=PENDING
            signal VcuTxMsg2_Sig2_oVcuTxMsg2_oTC37X_VCU_CAN00: start 32, 16 bit, little-endian, i-signal-type=PRIMITIVE, init-value=0, base-type=sint16, compu-method=CM_VcuTxMsg2_Sig2, data-constr=DC_VcuTxMsg2_Sig2, transfer-property=PENDING
            signal VcuTxMsg2_Sig3_oVcuTxMsg2_oTC37X_VCU_CAN00: start 48, 16 bit, little-endian, i-signal-type=PRIMITIVE, init-value=0, base-type=sint16, compu-method=CM_VcuTxMsg2_Sig3, data-constr=DC_VcuTxMsg2_Sig3, transfer-property=PENDING
        frame XCP_Request_oTC37X_VCU_CAN00: id 0x606, to VCU, frame-length=8, can-addressing-mode=STANDARD
          xcp pdu XCP_Request_oTC37X_VCU_CAN00: length=8
        frame XCP_Response_oTC37X_VCU_CAN00: id 0x607, from VCU, frame-length=8, can-addressing-mode=STANDARD
          xcp pdu XCP_Response_oTC37X_VCU_CAN00: length=8
        pdu triggering PT_Vcu_Uds_Func_Request: pdu=Vcu_Uds_Func_Request_oTC37X_VCU_CAN00, to VCU
        pdu triggering PT_Vcu_Uds_Phy_Request: pdu=Vcu_Uds_Phy_Request_oTC37X_VCU_CAN00, to VCU
        pdu triggering PT_Vcu_Uds_Response: pdu=Vcu_Uds_Response_oTC37X_VCU_CAN00, from VCU
    TC37X_VCU_CAN01  # VCU_CAN01
      can physical channel CHNL: comm-connectors=CN_TC37X_VCU_CAN01
        frame IBS_Status_06_oTC37X_VCU_CAN01: id 0xBC, to VCU, frame-length=8, can-addressing-mode=STANDARD
          pdu IBS_Status_06_oTC37X_VCU_CAN01: length=8, minimum-delay=0, transmission-mode-false-timing=cyclic-timing={time-offset=0, time-period=0.02}, transmission-mode-true-timing=cyclic-timing={time-offset=0, time-period=0.02}, unused-bit-pattern=0
            signal Checksum_0BC_oIBS_Status_06_oTC37X_VCU_CAN01: start 7, 8 bit, big-endian, i-signal-type=PRIMITIVE, init-value=0, base-type=uint8, compu-method=CM_Checksum_0BC, data-constr=DC_Checksum_0BC, transfer-property=PENDING, to VCU
            signal MessageCounter_0BC_oIBS_Status_06_oTC37X_VCU_CAN01: start 11, 4 bit, big-endian, i-signal-type=PRIMITIVE, init-value=0, base-type=uint8, compu-method=CM_MessageCounter_0BC, data-constr=DC_MessageCounter_0BC, transfer-property=PENDING, to VCU
            signal IBS_FactoryMode_oIBS_Status_06_oTC37X_VCU_CAN01: start 40, 1 bit, big-endian, i-signal-type=PRIMITIVE, init-value=0, base-type=boolean, compu-method=CM_IBS_FactoryMode, data-constr=DC_IBS_FactoryMode, transfer-property=PENDING, to VCU
            signal IBS_RollerbenchMode_oIBS_Status_06_oTC37X_VCU_CAN01: start 41, 1 bit, big-endian, i-signal-type=PRIMITIVE, init-value=0, base-type=boolean, compu-method=CM_IBS_RollerbenchMode, data-constr=DC_IBS_RollerbenchMode, transfer-property=PENDING, to VCU
            signal IBS_MaintenaceMode_oIBS_Status_06_oTC37X_VCU_CAN01: start 42, 1 bit, big-endian, i-signal-type=PRIMITIVE, init-value=0, base-type=boolean, compu-method=CM_IBS_MaintenaceMode, data-constr=DC_IBS_MaintenaceMode, transfer-property=PENDING, to VCU
            signal IBS_RWUAvailable_oIBS_Status_06_oTC37X_VCU_CAN01: start 43, 1 bit, big-endian, i-signal-type=PRIMITIVE, init-value=0, base-type=boolean, compu-method=CM_IBS_RWUAvailable, data-constr=DC_IBS_RWUAvailable, transfer-property=PENDING, to VCU
            signal IBS_RWUActive_oIBS_Status_06_oTC37X_VCU_CAN01: start 44, 1 bit, big-endian, i-signal-type=PRIMITIVE, init-value=0, base-type=boolean, compu-method=CM_IBS_RWUActive, data-constr=DC_IBS_RWUActive, transfer-property=PENDING, to VCU
            signal IBS_ESCOffSts_oIBS_Status_06_oTC37X_VCU_CAN01: start 45, 1 bit, big-endian, i-signal-type=PRIMITIVE, init-value=0, base-type=boolean, compu-method=CM_IBS_ESCOffSts, data-constr=DC_IBS_ESCOffSts, transfer-property=PENDING, to VCU
            signal IBS_HBAActive_oIBS_Status_06_oTC37X_VCU_CAN01: start 46, 1 bit, big-endian, i-signal-type=PRIMITIVE, init-value=0, base-type=boolean, compu-method=CM_IBS_HBAActive, data-constr=DC_IBS_HBAActive, transfer-property=PENDING, to VCU
            signal IBS_BrakeFluidWarning_oIBS_Status_06_oTC37X_VCU_CAN01: start 49, 2 bit, big-endian, i-signal-type=PRIMITIVE, init-value=0, base-type=uint8, compu-method=CM_IBS_BrakeFluidWarning, data-constr=DC_IBS_BrakeFluidWarning, transfer-property=PENDING, to VCU
            signal IBS_HDCSts_oIBS_Status_06_oTC37X_VCU_CAN01: start 51, 2 bit, big-endian, i-signal-type=PRIMITIVE, init-value=0, base-type=uint8, compu-method=CM_IBS_HDCSts, data-constr=DC_IBS_HDCSts, transfer-property=PENDING, to VCU
            signal IBS_ESClampdisplay_oIBS_Status_06_oTC37X_VCU_CAN01: start 53, 2 bit, big-endian, i-signal-type=PRIMITIVE, init-value=0, base-type=uint8, compu-method=CM_IBS_ESClampdisplay, data-constr=DC_IBS_ESClampdisplay, transfer-property=PENDING, to VCU
            signal IBS_AVHSts_oIBS_Status_06_oTC37X_VCU_CAN01: start 55, 2 bit, big-endian, i-signal-type=PRIMITIVE, init-value=0, base-type=uint8, compu-method=CM_IBS_AVHSts, data-constr=DC_IBS_AVHSts, transfer-property=PENDING, to VCU
            signal IBS_TireWarnFrntRi_oIBS_Status_06_oTC37X_VCU_CAN01: start 56, 1 bit, big-endian, i-signal-type=PRIMITIVE, init-value=0, base-type=boolean, compu-method=CM_IBS_TireWarnFrntRi, data-constr=DC_IBS_TireWarnFrntRi, transfer-property=PENDING, to VCU
            signal IBS_TireWarnFrntLe_oIBS_Status_06_oTC37X_VCU_CAN01: start 57, 1 bit, big-endian, i-signal-type=PRIMITIVE, init-value=0, base-type=boolean, compu-method=CM_IBS_TireWarnFrntLe, data-constr=DC_IBS_TireWarnFrntLe, transfer-property=PENDING, to VCU
            signal IBS_TireWarnReRi_oIBS_Status_06_oTC37X_VCU_CAN01: start 58, 1 bit, big-endian, i-signal-type=PRIMITIVE, init-value=0, base-type=boolean, compu-method=CM_IBS_TireWarnReRi, data-constr=DC_IBS_TireWarnReRi, transfer-property=PENDING, to VCU
            signal IBS_TireWarnReLe_oIBS_Status_06_oTC37X_VCU_CAN01: start 59, 1 bit, big-endian, i-signal-type=PRIMITIVE, init-value=0, base-type=boolean, compu-method=CM_IBS_TireWarnReLe, data-constr=DC_IBS_TireWarnReLe, transfer-property=PENDING, to VCU
            signal IBS_TPMS_ResetSts_oIBS_Status_06_oTC37X_VCU_CAN01: start 60, 1 bit, big-endian, i-signal-type=PRIMITIVE, init-value=0, base-type=boolean, compu-method=CM_IBS_TPMS_ResetSts, data-constr=DC_IBS_TPMS_ResetSts, transfer-property=PENDING, to VCU
            signal IBS_TireMonSysSts_oIBS_Status_06_oTC37X_VCU_CAN01: start 61, 1 bit, big-endian, i-signal-type=PRIMITIVE, init-value=0, base-type=boolean, compu-method=CM_IBS_TireMonSysSts, data-constr=DC_IBS_TireMonSysSts, transfer-property=PENDING, to VCU
            signal IBS_EPBFailureStatus_oIBS_Status_06_oTC37X_VCU_CAN01: start 63, 2 bit, big-endian, i-signal-type=PRIMITIVE, init-value=0, base-type=uint8, compu-method=CM_IBS_EPBFailureStatus, data-constr=DC_IBS_EPBFailureStatus, transfer-property=PENDING, to VCU
            mapping SG_IBS_Status_06_Signal_Group: i-signal-group=SG_IBS_Status_06_Signal_Group_oIBS_Status_06_oTC37X_VCU_CAN01, transfer-property=PENDING
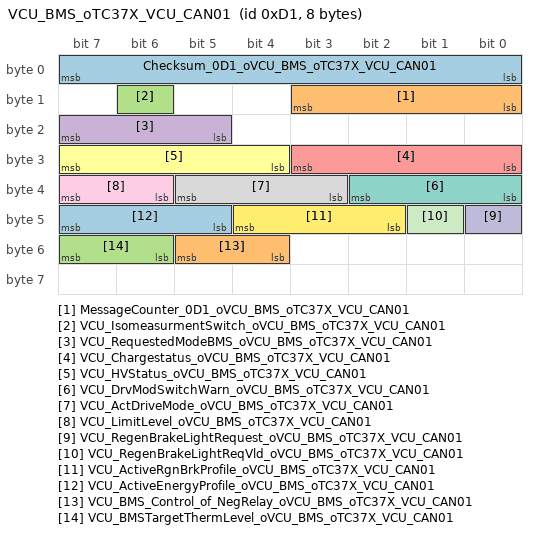
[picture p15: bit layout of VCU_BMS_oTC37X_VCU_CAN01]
        frame VCU_BMS_oTC37X_VCU_CAN01: id 0xD1, from VCU, frame-length=8, can-addressing-mode=STANDARD
          pdu VCU_BMS_oTC37X_VCU_CAN01: length=8, minimum-delay=0, transmission-mode-false-timing=cyclic-timing={time-offset=0, time-period=0.02}, transmission-mode-true-timing=cyclic-timing={time-offset=0, time-period=0.02}, unused-bit-pattern=0
            signal Checksum_0D1_oVCU_BMS_oTC37X_VCU_CAN01: start 7, 8 bit, big-endian, i-signal-type=PRIMITIVE, init-value=0, base-type=uint8, compu-method=CM_Checksum_0D1, data-constr=DC_Checksum_0D1, transfer-property=PENDING
            signal MessageCounter_0D1_oVCU_BMS_oTC37X_VCU_CAN01: start 11, 4 bit, big-endian, i-signal-type=PRIMITIVE, init-value=0, base-type=uint8, compu-method=CM_MessageCounter_0D1, data-constr=DC_MessageCounter_0D1, transfer-property=PENDING
            signal VCU_IsomeasurmentSwitch_oVCU_BMS_oTC37X_VCU_CAN01: start 14, 1 bit, big-endian, i-signal-type=PRIMITIVE, init-value=0, base-type=boolean, compu-method=CM_VCU_IsomeasurmentSwitch, data-constr=DC_VCU_IsomeasurmentSwitch, transfer-property=PENDING
            signal VCU_RequestedModeBMS_oVCU_BMS_oTC37X_VCU_CAN01: start 23, 3 bit, big-endian, i-signal-type=PRIMITIVE, init-value=0, base-type=uint8, compu-method=CM_VCU_RequestedModeBMS, data-constr=DC_VCU_RequestedModeBMS, transfer-property=PENDING
            signal VCU_Chargestatus_oVCU_BMS_oTC37X_VCU_CAN01: start 27, 4 bit, big-endian, i-signal-type=PRIMITIVE, init-value=0, base-type=uint8, compu-method=CM_VCU_Chargestatus, data-constr=DC_VCU_Chargestatus, transfer-property=PENDING
            signal VCU_HVStatus_oVCU_BMS_oTC37X_VCU_CAN01: start 31, 4 bit, big-endian, i-signal-type=PRIMITIVE, init-value=0, base-type=uint8, compu-method=CM_VCU_HVStatus, data-constr=DC_VCU_HVStatus, transfer-property=PENDING
            signal VCU_DrvModSwitchWarn_oVCU_BMS_oTC37X_VCU_CAN01: start 34, 3 bit, big-endian, i-signal-type=PRIMITIVE, init-value=0, base-type=uint8, compu-method=CM_VCU_DrvModSwitchWarn, data-constr=DC_VCU_DrvModSwitchWarn, transfer-property=PENDING
            signal VCU_ActDriveMode_oVCU_BMS_oTC37X_VCU_CAN01: start 37, 3 bit, big-endian, i-signal-type=PRIMITIVE, init-value=0, base-type=uint8, compu-method=CM_VCU_ActDriveMode, data-constr=DC_VCU_ActDriveMode, transfer-property=PENDING
            signal VCU_LimitLevel_oVCU_BMS_oTC37X_VCU_CAN01: start 39, 2 bit, big-endian, i-signal-type=PRIMITIVE, init-value=0, base-type=uint8, compu-method=CM_VCU_LimitLevel, data-constr=DC_VCU_LimitLevel, transfer-property=PENDING
            signal VCU_RegenBrakeLightRequest_oVCU_BMS_oTC37X_VCU_CAN01: start 40, 1 bit, big-endian, i-signal-type=PRIMITIVE, init-value=0, base-type=boolean, compu-method=CM_VCU_RegenBrakeLightRequest, data-constr=DC_VCU_RegenBrakeLightRequest, transfer-property=PENDING
            signal VCU_RegenBrakeLightReqVld_oVCU_BMS_oTC37X_VCU_CAN01: start 41, 1 bit, big-endian, i-signal-type=PRIMITIVE, init-value=0, base-type=boolean, compu-method=CM_VCU_RegenBrakeLightReqVld, data-constr=DC_VCU_RegenBrakeLightReqVld, transfer-property=PENDING
            signal VCU_ActiveRgnBrkProfile_oVCU_BMS_oTC37X_VCU_CAN01: start 44, 3 bit, big-endian, i-signal-type=PRIMITIVE, init-value=0, base-type=uint8, compu-method=CM_VCU_ActiveRgnBrkProfile, data-constr=DC_VCU_ActiveRgnBrkProfile, transfer-property=PENDING
            signal VCU_ActiveEnergyProfile_oVCU_BMS_oTC37X_VCU_CAN01: start 47, 3 bit, big-endian, i-signal-type=PRIMITIVE, init-value=0, base-type=uint8, compu-method=CM_VCU_ActiveEnergyProfile, data-constr=DC_VCU_ActiveEnergyProfile, transfer-property=PENDING
            signal VCU_BMS_Control_of_NegRelay_oVCU_BMS_oTC37X_VCU_CAN01: start 53, 2 bit, big-endian, i-signal-type=PRIMITIVE, init-value=0, base-type=uint8, compu-method=CM_VCU_BMS_Control_of_NegRelay, data-constr=DC_VCU_BMS_Control_of_NegRelay, transfer-property=PENDING
            signal VCU_BMSTargetThermLevel_oVCU_BMS_oTC37X_VCU_CAN01: start 55, 2 bit, big-endian, i-signal-type=PRIMITIVE, init-value=0, base-type=uint8, compu-method=CM_VCU_BMSTargetThermLevel, data-constr=DC_VCU_BMSTargetThermLevel, transfer-property=PENDING
            mapping SG_VCU_BMS_Signal_Group: i-signal-group=SG_VCU_BMS_Signal_Group_oVCU_BMS_oTC37X_VCU_CAN01, transfer-property=PENDING
        frame VCU_Rx_500h_NM_oTC37X_VCU_CAN01: id 0x500, to VCU, frame-length=8, can-addressing-mode=STANDARD
          nm pdu VCU_Rx_500h_NM_oTC37X_VCU_CAN01: length=8, unused-bit-pattern=0
        frame VCU_Tx_51Ch_NM_oTC37X_VCU_CAN01: id 0x51C, from VCU, frame-length=8, can-addressing-mode=STANDARD
          nm pdu VCU_Tx_51Ch_NM_oTC37X_VCU_CAN01: length=8, unused-bit-pattern=0
            signal VCU_Tx_51Ch_NM_UserData_oVCU_Tx_51Ch_NM_oTC37X_VCU_CAN01: start 16, 48 bit, opaque, i-signal-type=ARRAY, init-value=6 x 0, base-type=uint8_6_none, compu-method=CM_VCU_Tx_51Ch_NM_UserData, data-constr=DC_VCU_Tx_51Ch_NM_UserData, transfer-property=PENDING
        frame VcuAdcTxMsg1_oTC37X_VCU_CAN01: id 0x102, from VCU, frame-length=8, can-addressing-mode=STANDARD
          pdu VcuAdcTxMsg1_oTC37X_VCU_CAN01: length=8, minimum-delay=0, transmission-mode-false-timing=cyclic-timing={time-offset=0, time-period=0.5}, transmission-mode-true-timing=cyclic-timing={time-offset=0, time-period=0.5}, unused-bit-pattern=0
            signal VcuAdcTxMsg1_Sig0_oVcuAdcTxMsg1_oTC37X_VCU_CAN01: start 0, 16 bit, little-endian, i-signal-type=PRIMITIVE, init-value=0, base-type=sint16, compu-method=CM_VcuAdcTxMsg1_Sig0, data-constr=DC_VcuAdcTxMsg1_Sig0, transfer-property=PENDING
            signal VcuAdcTxMsg1_Sig1_oVcuAdcTxMsg1_oTC37X_VCU_CAN01: start 16, 16 bit, little-endian, i-signal-type=PRIMITIVE, init-value=0, base-type=sint16, compu-method=CM_VcuAdcTxMsg1_Sig1, data-constr=DC_VcuAdcTxMsg1_Sig1, transfer-property=PENDING
            signal VcuAdcTxMsg1_Sig2_oVcuAdcTxMsg1_oTC37X_VCU_CAN01: start 32, 16 bit, little-endian, i-signal-type=PRIMITIVE, init-value=0, base-type=sint16, compu-method=CM_VcuAdcTxMsg1_Sig2, data-constr=DC_VcuAdcTxMsg1_Sig2, transfer-property=PENDING
            signal VcuAdcTxMsg1_Sig3_oVcuAdcTxMsg1_oTC37X_VCU_CAN01: start 48, 16 bit, little-endian, i-signal-type=PRIMITIVE, init-value=0, base-type=sint16, compu-method=CM_VcuAdcTxMsg1_Sig3, data-constr=DC_VcuAdcTxMsg1_Sig3, transfer-property=PENDING
        frame VcuAdcTxMsg2_oTC37X_VCU_CAN01: id 0x103, from VCU, frame-length=8, can-addressing-mode=STANDARD
          pdu VcuAdcTxMsg2_oTC37X_VCU_CAN01: length=8, minimum-delay=0, transmission-mode-false-timing=cyclic-timing={time-offset=0, time-period=0.5}, transmission-mode-true-timing=cyclic-timing={time-offset=0, time-period=0.5}, unused-bit-pattern=0
            signal VcuAdcTxMsg2_Sig0_oVcuAdcTxMsg2_oTC37X_VCU_CAN01: start 0, 16 bit, little-endian, i-signal-type=PRIMITIVE, init-value=0, base-type=sint16, compu-method=CM_VcuAdcTxMsg2_Sig0, data-constr=DC_VcuAdcTxMsg2_Sig0, transfer-property=PENDING
            signal VcuAdcTxMsg2_Sig1_oVcuAdcTxMsg2_oTC37X_VCU_CAN01: start 16, 16 bit, little-endian, i-signal-type=PRIMITIVE, init-value=0, base-type=sint16, compu-method=CM_VcuAdcTxMsg2_Sig1, data-constr=DC_VcuAdcTxMsg2_Sig1, transfer-property=PENDING
            signal VcuAdcTxMsg2_Sig2_oVcuAdcTxMsg2_oTC37X_VCU_CAN01: start 32, 16 bit, little-endian, i-signal-type=PRIMITIVE, init-value=0, base-type=sint16, compu-method=CM_VcuAdcTxMsg2_Sig2, data-constr=DC_VcuAdcTxMsg2_Sig2, transfer-property=PENDING
            signal VcuAdcTxMsg2_Sig3_oVcuAdcTxMsg2_oTC37X_VCU_CAN01: start 48, 16 bit, little-endian, i-signal-type=PRIMITIVE, init-value=0, base-type=sint16, compu-method=CM_VcuAdcTxMsg2_Sig3, data-constr=DC_VcuAdcTxMsg2_Sig3, transfer-property=PENDING
        frame VcuRxMsg3_oTC37X_VCU_CAN01: id 0x202, to VCU, frame-length=8, can-addressing-mode=STANDARD
          pdu VcuRxMsg3_oTC37X_VCU_CAN01: length=8, minimum-delay=0, transmission-mode-false-timing=cyclic-timing={time-offset=0, time-period=0.5}, transmission-mode-true-timing=cyclic-timing={time-offset=0, time-period=0.5}, unused-bit-pattern=0
            signal VcuRxMsg3_Sig0_oVcuRxMsg3_oTC37X_VCU_CAN01: start 0, 16 bit, little-endian, i-signal-type=PRIMITIVE, init-value=0, base-type=sint16, compu-method=CM_VcuRxMsg3_Sig0, data-constr=DC_VcuRxMsg3_Sig0, transfer-property=PENDING, to VCU
            signal VcuRxMsg3_Sig1_oVcuRxMsg3_oTC37X_VCU_CAN01: start 16, 16 bit, little-endian, i-signal-type=PRIMITIVE, init-value=0, base-type=sint16, compu-method=CM_VcuRxMsg3_Sig1, data-constr=DC_VcuRxMsg3_Sig1, transfer-property=PENDING, to VCU
            signal VcuRxMsg3_Sig2_oVcuRxMsg3_oTC37X_VCU_CAN01: start 32, 16 bit, little-endian, i-signal-type=PRIMITIVE, init-value=0, base-type=sint16, compu-method=CM_VcuRxMsg3_Sig2, data-constr=DC_VcuRxMsg3_Sig2, transfer-property=PENDING, to VCU
            signal VcuRxMsg3_Sig3_oVcuRxMsg3_oTC37X_VCU_CAN01: start 48, 16 bit, little-endian, i-signal-type=PRIMITIVE, init-value=0, base-type=sint16, compu-method=CM_VcuRxMsg3_Sig3, data-constr=DC_VcuRxMsg3_Sig3, transfer-property=PENDING, to VCU
        frame VcuRxMsg4_oTC37X_VCU_CAN01: id 0x203, to VCU, frame-length=8, can-addressing-mode=STANDARD
          pdu VcuRxMsg4_oTC37X_VCU_CAN01: length=8, minimum-delay=0, transmission-mode-false-timing=cyclic-timing={time-offset=0, time-period=0.5}, transmission-mode-true-timing=cyclic-timing={time-offset=0, time-period=0.5}, unused-bit-pattern=0
            signal VcuRxMsg4_Sig0_oVcuRxMsg4_oTC37X_VCU_CAN01: start 0, 16 bit, little-endian, i-signal-type=PRIMITIVE, init-value=0, base-type=sint16, compu-method=CM_VcuRxMsg4_Sig0, data-constr=DC_VcuRxMsg4_Sig0, transfer-property=PENDING, to VCU
            signal VcuRxMsg4_Sig1_oVcuRxMsg4_oTC37X_VCU_CAN01: start 16, 16 bit, little-endian, i-signal-type=PRIMITIVE, init-value=0, base-type=sint16, compu-method=CM_VcuRxMsg4_Sig1, data-constr=DC_VcuRxMsg4_Sig1, transfer-property=PENDING, to VCU
            signal VcuRxMsg4_Sig2_oVcuRxMsg4_oTC37X_VCU_CAN01: start 32, 16 bit, little-endian, i-signal-type=PRIMITIVE, init-value=0, base-type=sint16, compu-method=CM_VcuRxMsg4_Sig2, data-constr=DC_VcuRxMsg4_Sig2, transfer-property=PENDING, to VCU
            signal VcuRxMsg4_Sig3_oVcuRxMsg4_oTC37X_VCU_CAN01: start 48, 16 bit, little-endian, i-signal-type=PRIMITIVE, init-value=0, base-type=sint16, compu-method=CM_VcuRxMsg4_Sig3, data-constr=DC_VcuRxMsg4_Sig3, transfer-property=PENDING, to VCU
    TC37X_VCU_CAN03  # VCU_CAN03
      can physical channel CHNL: comm-connectors=CN_TC37X_VCU_CAN03
        frame VCU_Rx_500h_NM_oTC37X_VCU_CAN03: id 0x500, to VCU, frame-length=8, can-addressing-mode=STANDARD
          nm pdu VCU_Rx_500h_NM_oTC37X_VCU_CAN03: length=8, unused-bit-pattern=0
        frame VCU_Tx_51Ch_NM_oTC37X_VCU_CAN03: id 0x51C, from VCU, frame-length=8, can-addressing-mode=STANDARD
          nm pdu VCU_Tx_51Ch_NM_oTC37X_VCU_CAN03: length=8, unused-bit-pattern=0
            signal VCU_Tx_51Ch_NM_UserData_oVCU_Tx_51Ch_NM_oTC37X_VCU_CAN03: start 16, 48 bit, opaque, i-signal-type=ARRAY, init-value=6 x 0, base-type=uint8_6_none, compu-method=CM_VCU_Tx_51Ch_NM_UserData, data-constr=DC_VCU_Tx_51Ch_NM_UserData, transfer-property=PENDING
        frame VcuCan03RxMsg1_oTC37X_VCU_CAN03: id 0x212, to VCU, frame-length=8, can-addressing-mode=STANDARD
          pdu VcuCan03RxMsg1_oTC37X_VCU_CAN03: length=8, minimum-delay=0, transmission-mode-false-timing=cyclic-timing={time-offset=0, time-period=0.5}, transmission-mode-true-timing=cyclic-timing={time-offset=0, time-period=0.5}, unused-bit-pattern=0
            signal VcuRxMsg3_Sig0_oVcuCan03RxMsg1_oTC37X_VCU_CAN03: start 0, 16 bit, little-endian, i-signal-type=PRIMITIVE, init-value=0, base-type=sint16, compu-method=CM_VcuRxMsg3_Sig0, data-constr=DC_VcuRxMsg3_Sig0, transfer-property=PENDING, to VCU
            signal VcuRxMsg3_Sig1_oVcuCan03RxMsg1_oTC37X_VCU_CAN03: start 16, 16 bit, little-endian, i-signal-type=PRIMITIVE, init-value=0, base-type=sint16, compu-method=CM_VcuRxMsg3_Sig1, data-constr=DC_VcuRxMsg3_Sig1, transfer-property=PENDING, to VCU
            signal VcuRxMsg3_Sig2_oVcuCan03RxMsg1_oTC37X_VCU_CAN03: start 32, 16 bit, little-endian, i-signal-type=PRIMITIVE, init-value=0, base-type=sint16, compu-method=CM_VcuRxMsg3_Sig2, data-constr=DC_VcuRxMsg3_Sig2, transfer-property=PENDING, to VCU
            signal VcuRxMsg3_Sig3_oVcuCan03RxMsg1_oTC37X_VCU_CAN03: start 48, 16 bit, little-endian, i-signal-type=PRIMITIVE, init-value=0, base-type=sint16, compu-method=CM_VcuRxMsg3_Sig3, data-constr=DC_VcuRxMsg3_Sig3, transfer-property=PENDING, to VCU
        frame VcuCan03RxMsg2_oTC37X_VCU_CAN03: id 0x213, to VCU, frame-length=8, can-addressing-mode=STANDARD
          pdu VcuCan03RxMsg2_oTC37X_VCU_CAN03: length=8, minimum-delay=0, transmission-mode-false-timing=cyclic-timing={time-offset=0, time-period=0.5}, transmission-mode-true-timing=cyclic-timing={time-offset=0, time-period=0.5}, unused-bit-pattern=0
            signal VcuRxMsg4_Sig0_oVcuCan03RxMsg2_oTC37X_VCU_CAN03: start 0, 16 bit, little-endian, i-signal-type=PRIMITIVE, init-value=0, base-type=sint16, compu-method=CM_VcuRxMsg4_Sig0, data-constr=DC_VcuRxMsg4_Sig0, transfer-property=PENDING, to VCU
            signal VcuRxMsg4_Sig1_oVcuCan03RxMsg2_oTC37X_VCU_CAN03: start 16, 16 bit, little-endian, i-signal-type=PRIMITIVE, init-value=0, base-type=sint16, compu-method=CM_VcuRxMsg4_Sig1, data-constr=DC_VcuRxMsg4_Sig1, transfer-property=PENDING, to VCU
            signal VcuRxMsg4_Sig2_oVcuCan03RxMsg2_oTC37X_VCU_CAN03: start 32, 16 bit, little-endian, i-signal-type=PRIMITIVE, init-value=0, base-type=sint16, compu-method=CM_VcuRxMsg4_Sig2, data-constr=DC_VcuRxMsg4_Sig2, transfer-property=PENDING, to VCU
            signal VcuRxMsg4_Sig3_oVcuCan03RxMsg2_oTC37X_VCU_CAN03: start 48, 16 bit, little-endian, i-signal-type=PRIMITIVE, init-value=0, base-type=sint16, compu-method=CM_VcuRxMsg4_Sig3, data-constr=DC_VcuRxMsg4_Sig3, transfer-property=PENDING, to VCU
        frame VcuCan03TxMsg1_oTC37X_VCU_CAN03: id 0x112, from VCU, frame-length=8, can-addressing-mode=STANDARD
          pdu VcuCan03TxMsg1_oTC37X_VCU_CAN03: length=8, minimum-delay=0, transmission-mode-false-timing=cyclic-timing={time-offset=0, time-period=0.5}, transmission-mode-true-timing=cyclic-timing={time-offset=0, time-period=0.5}, unused-bit-pattern=0
            signal VcuAdcTxMsg1_Sig0_oVcuCan03TxMsg1_oTC37X_VCU_CAN03: start 0, 16 bit, little-endian, i-signal-type=PRIMITIVE, init-value=0, base-type=sint16, compu-method=CM_VcuAdcTxMsg1_Sig0, data-constr=DC_VcuAdcTxMsg1_Sig0, transfer-property=PENDING
            signal VcuAdcTxMsg1_Sig1_oVcuCan03TxMsg1_oTC37X_VCU_CAN03: start 16, 16 bit, little-endian, i-signal-type=PRIMITIVE, init-value=0, base-type=sint16, compu-method=CM_VcuAdcTxMsg1_Sig1, data-constr=DC_VcuAdcTxMsg1_Sig1, transfer-property=PENDING
            signal VcuAdcTxMsg1_Sig2_oVcuCan03TxMsg1_oTC37X_VCU_CAN03: start 32, 16 bit, little-endian, i-signal-type=PRIMITIVE, init-value=0, base-type=sint16, compu-method=CM_VcuAdcTxMsg1_Sig2, data-constr=DC_VcuAdcTxMsg1_Sig2, transfer-property=PENDING
            signal VcuAdcTxMsg1_Sig3_oVcuCan03TxMsg1_oTC37X_VCU_CAN03: start 48, 16 bit, little-endian, i-signal-type=PRIMITIVE, init-value=0, base-type=sint16, compu-method=CM_VcuAdcTxMsg1_Sig3, data-constr=DC_VcuAdcTxMsg1_Sig3, transfer-property=PENDING
        frame VcuCan03TxMsg2_oTC37X_VCU_CAN03: id 0x113, from VCU, frame-length=8, can-addressing-mode=STANDARD
          pdu VcuCan03TxMsg2_oTC37X_VCU_CAN03: length=8, minimum-delay=0, transmission-mode-false-timing=cyclic-timing={time-offset=0, time-period=0.5}, transmission-mode-true-timing=cyclic-timing={time-offset=0, time-period=0.5}, unused-bit-pattern=0
            signal VcuAdcTxMsg2_Sig0_oVcuCan03TxMsg2_oTC37X_VCU_CAN03: start 0, 16 bit, little-endian, i-signal-type=PRIMITIVE, init-value=0, base-type=sint16, compu-method=CM_VcuAdcTxMsg2_Sig0, data-constr=DC_VcuAdcTxMsg2_Sig0, transfer-property=PENDING
            signal VcuAdcTxMsg2_Sig1_oVcuCan03TxMsg2_oTC37X_VCU_CAN03: start 16, 16 bit, little-endian, i-signal-type=PRIMITIVE, init-value=0, base-type=sint16, compu-method=CM_VcuAdcTxMsg2_Sig1, data-constr=DC_VcuAdcTxMsg2_Sig1, transfer-property=PENDING
            signal VcuAdcTxMsg2_Sig2_oVcuCan03TxMsg2_oTC37X_VCU_CAN03: start 32, 16 bit, little-endian, i-signal-type=PRIMITIVE, init-value=0, base-type=sint16, compu-method=CM_VcuAdcTxMsg2_Sig2, data-constr=DC_VcuAdcTxMsg2_Sig2, transfer-property=PENDING
            signal VcuAdcTxMsg2_Sig3_oVcuCan03TxMsg2_oTC37X_VCU_CAN03: start 48, 16 bit, little-endian, i-signal-type=PRIMITIVE, init-value=0, base-type=sint16, compu-method=CM_VcuAdcTxMsg2_Sig3, data-constr=DC_VcuAdcTxMsg2_Sig3, transfer-property=PENDING
  lin cluster LIN00: baudrate=19200, protocol-name=LIN, protocol-version=LIN21  # /*************************************************************************************/ // // Description: // Created: // Author: // Version: // Vehicle Project: // /*************************************************************************************/
    lin physical channel CHNL: comm-connectors=CN_LIN00
      frame EDCU_EXV2_oLIN00: id 0x22, from VCU, frame-length=8, lin-checksum=ENHANCED
        pdu EDCU_EXV2_oLIN00: length=8, unused-bit-pattern=255
          signal EDCU_EXV2_Cmd_Set_Rq_oEDCU_EXV2_oLIN00: start 0, 16 bit, little-endian, i-signal-type=PRIMITIVE, init-value=0, base-type=uint16, compu-method=CM_EDCU_EXV2_Cmd_Set_Rq, data-constr=DC_EDCU_EXV2_Cmd_Set_Rq
          signal EDCU_EXV2_Cmd_Move_Enbl_oEDCU_EXV2_oLIN00: start 16, 1 bit, little-endian, i-signal-type=PRIMITIVE, init-value=0, base-type=boolean, compu-method=CM_EDCU_EXV2_Cmd_Move_Enbl, data-constr=DC_EDCU_EXV2_Cmd_Move_Enbl
          signal EDCU_EXV2_Cmd_Init_Rq_oEDCU_EXV2_oLIN00: start 24, 3 bit, little-endian, i-signal-type=PRIMITIVE, init-value=0, base-type=uint8, compu-method=CM_EDCU_EXV2_Cmd_Init_Rq, data-constr=DC_EDCU_EXV2_Cmd_Init_Rq
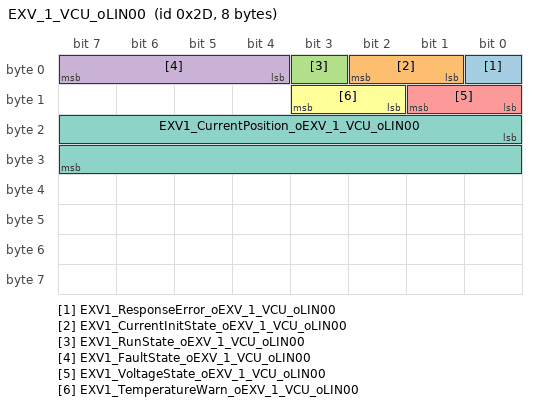
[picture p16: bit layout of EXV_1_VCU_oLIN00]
      frame EXV_1_VCU_oLIN00: id 0x2D, to VCU, frame-length=8, lin-checksum=ENHANCED
        pdu EXV_1_VCU_oLIN00: length=8, unused-bit-pattern=255
          signal EXV1_ResponseError_oEXV_1_VCU_oLIN00: start 0, 1 bit, little-endian, i-signal-type=PRIMITIVE, init-value=0, base-type=boolean, compu-method=CM_EXV1_ResponseError, data-constr=DC_EXV1_ResponseError, to VCU
          signal EXV1_CurrentInitState_oEXV_1_VCU_oLIN00: start 1, 2 bit, little-endian, i-signal-type=PRIMITIVE, init-value=0, base-type=uint8, compu-method=CM_EXV1_CurrentInitState, data-constr=DC_EXV1_CurrentInitState, to VCU
          signal EXV1_RunState_oEXV_1_VCU_oLIN00: start 3, 1 bit, little-endian, i-signal-type=PRIMITIVE, init-value=0, base-type=boolean, compu-method=CM_EXV1_RunState, data-constr=DC_EXV1_RunState, to VCU
          signal EXV1_FaultState_oEXV_1_VCU_oLIN00: start 4, 4 bit, little-endian, i-signal-type=PRIMITIVE, init-value=0, base-type=uint8, compu-method=CM_EXV1_FaultState, data-constr=DC_EXV1_FaultState, to VCU
          signal EXV1_VoltageState_oEXV_1_VCU_oLIN00: start 8, 2 bit, little-endian, i-signal-type=PRIMITIVE, init-value=0, base-type=uint8, compu-method=CM_EXV1_VoltageState, data-constr=DC_EXV1_VoltageState, to VCU
          signal EXV1_TemperatureWarn_oEXV_1_VCU_oLIN00: start 10, 2 bit, little-endian, i-signal-type=PRIMITIVE, init-value=0, base-type=uint8, compu-method=CM_EXV1_TemperatureWarn, data-constr=DC_EXV1_TemperatureWarn, to VCU
          signal EXV1_CurrentPosition_oEXV_1_VCU_oLIN00: start 16, 16 bit, little-endian, i-signal-type=PRIMITIVE, init-value=0, base-type=uint16, compu-method=CM_EXV1_CurrentPosition, data-constr=DC_EXV1_CurrentPosition, to VCU
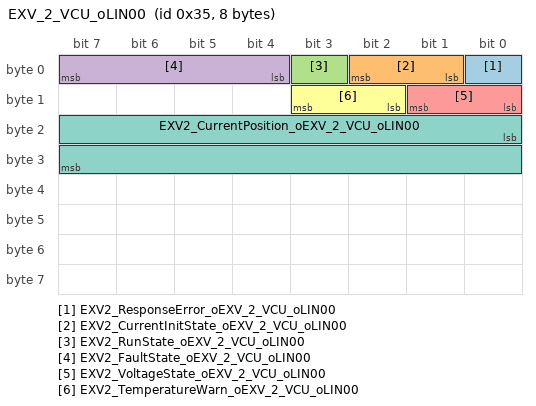
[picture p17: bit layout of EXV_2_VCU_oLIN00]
      frame EXV_2_VCU_oLIN00: id 0x35, to VCU, frame-length=8, lin-checksum=ENHANCED
        pdu EXV_2_VCU_oLIN00: length=8, unused-bit-pattern=255
          signal EXV2_ResponseError_oEXV_2_VCU_oLIN00: start 0, 1 bit, little-endian, i-signal-type=PRIMITIVE, init-value=0, base-type=boolean, compu-method=CM_EXV2_ResponseError, data-constr=DC_EXV2_ResponseError, to VCU
          signal EXV2_CurrentInitState_oEXV_2_VCU_oLIN00: start 1, 2 bit, little-endian, i-signal-type=PRIMITIVE, init-value=0, base-type=uint8, compu-method=CM_EXV2_CurrentInitState, data-constr=DC_EXV2_CurrentInitState, to VCU
          signal EXV2_RunState_oEXV_2_VCU_oLIN00: start 3, 1 bit, little-endian, i-signal-type=PRIMITIVE, init-value=0, base-type=boolean, compu-method=CM_EXV2_RunState, data-constr=DC_EXV2_RunState, to VCU
          signal EXV2_FaultState_oEXV_2_VCU_oLIN00: start 4, 4 bit, little-endian, i-signal-type=PRIMITIVE, init-value=0, base-type=uint8, compu-method=CM_EXV2_FaultState, data-constr=DC_EXV2_FaultState, to VCU
          signal EXV2_VoltageState_oEXV_2_VCU_oLIN00: start 8, 2 bit, little-endian, i-signal-type=PRIMITIVE, init-value=0, base-type=uint8, compu-method=CM_EXV2_VoltageState, data-constr=DC_EXV2_VoltageState, to VCU
          signal EXV2_TemperatureWarn_oEXV_2_VCU_oLIN00: start 10, 2 bit, little-endian, i-signal-type=PRIMITIVE, init-value=0, base-type=uint8, compu-method=CM_EXV2_TemperatureWarn, data-constr=DC_EXV2_TemperatureWarn, to VCU
          signal EXV2_CurrentPosition_oEXV_2_VCU_oLIN00: start 16, 16 bit, little-endian, i-signal-type=PRIMITIVE, init-value=0, base-type=uint16, compu-method=CM_EXV2_CurrentPosition, data-constr=DC_EXV2_CurrentPosition, to VCU
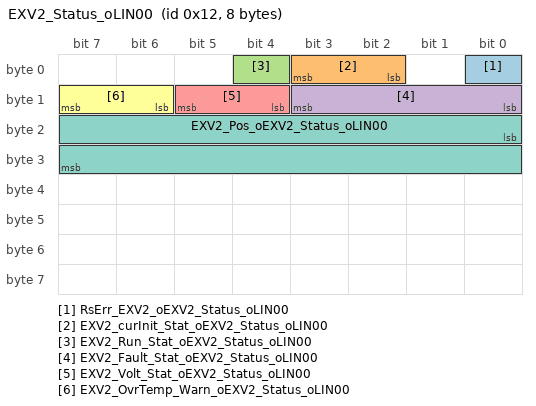
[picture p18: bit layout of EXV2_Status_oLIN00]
      frame EXV2_Status_oLIN00: id 0x12, to VCU, frame-length=8, lin-checksum=ENHANCED
        pdu EXV2_Status_oLIN00: length=8, unused-bit-pattern=255
          signal RsErr_EXV2_oEXV2_Status_oLIN00: start 0, 1 bit, little-endian, i-signal-type=PRIMITIVE, init-value=0, base-type=boolean, compu-method=CM_RsErr_EXV2, data-constr=DC_RsErr_EXV2, to VCU
          signal EXV2_curInit_Stat_oEXV2_Status_oLIN00: start 2, 2 bit, little-endian, i-signal-type=PRIMITIVE, init-value=0, base-type=uint8, compu-method=CM_EXV2_curInit_Stat, data-constr=DC_EXV2_curInit_Stat, to VCU
          signal EXV2_Run_Stat_oEXV2_Status_oLIN00: start 4, 1 bit, little-endian, i-signal-type=PRIMITIVE, init-value=0, base-type=boolean, compu-method=CM_EXV2_Run_Stat, data-constr=DC_EXV2_Run_Stat, to VCU
          signal EXV2_Fault_Stat_oEXV2_Status_oLIN00: start 8, 4 bit, little-endian, i-signal-type=PRIMITIVE, init-value=0, base-type=uint8, compu-method=CM_EXV2_Fault_Stat, data-constr=DC_EXV2_Fault_Stat, to VCU
          signal EXV2_Volt_Stat_oEXV2_Status_oLIN00: start 12, 2 bit, little-endian, i-signal-type=PRIMITIVE, init-value=0, base-type=uint8, compu-method=CM_EXV2_Volt_Stat, data-constr=DC_EXV2_Volt_Stat, to VCU
          signal EXV2_OvrTemp_Warn_oEXV2_Status_oLIN00: start 14, 2 bit, little-endian, i-signal-type=PRIMITIVE, init-value=0, base-type=uint8, compu-method=CM_EXV2_OvrTemp_Warn, data-constr=DC_EXV2_OvrTemp_Warn, to VCU
          signal EXV2_Pos_oEXV2_Status_oLIN00: start 16, 16 bit, little-endian, i-signal-type=PRIMITIVE, init-value=0, base-type=uint16, compu-method=CM_EXV2_Pos, data-constr=DC_EXV2_Pos, to VCU
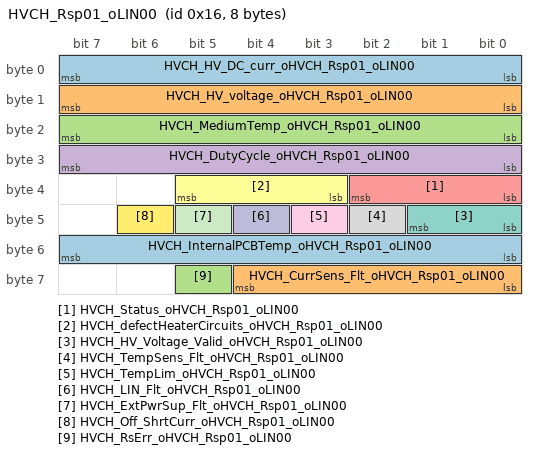
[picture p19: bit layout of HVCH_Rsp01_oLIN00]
      frame HVCH_Rsp01_oLIN00: id 0x16, to VCU, frame-length=8, lin-checksum=ENHANCED
        pdu HVCH_Rsp01_oLIN00: length=8, unused-bit-pattern=255
          signal HVCH_HV_DC_curr_oHVCH_Rsp01_oLIN00: start 0, 8 bit, little-endian, i-signal-type=PRIMITIVE, init-value=0, base-type=uint8, compu-method=CM_HVCH_HV_DC_curr, data-constr=DC_HVCH_HV_DC_curr, unit=U_A, to VCU
          signal HVCH_HV_voltage_oHVCH_Rsp01_oLIN00: start 8, 8 bit, little-endian, i-signal-type=PRIMITIVE, init-value=0, base-type=uint8, compu-method=CM_HVCH_HV_voltage, data-constr=DC_HVCH_HV_voltage, unit=U_V, to VCU
          signal HVCH_MediumTemp_oHVCH_Rsp01_oLIN00: start 16, 8 bit, little-endian, i-signal-type=PRIMITIVE, init-value=0, base-type=uint8, compu-method=CM_HVCH_MediumTemp, data-constr=DC_HVCH_MediumTemp, unit=U_celsius, to VCU
          signal HVCH_DutyCycle_oHVCH_Rsp01_oLIN00: start 24, 8 bit, little-endian, i-signal-type=PRIMITIVE, init-value=50, base-type=uint8, compu-method=CM_HVCH_DutyCycle, data-constr=DC_HVCH_DutyCycle, unit=U_percent, to VCU
          signal HVCH_Status_oHVCH_Rsp01_oLIN00: start 32, 3 bit, little-endian, i-signal-type=PRIMITIVE, init-value=0, base-type=uint8, compu-method=CM_HVCH_Status, data-constr=DC_HVCH_Status, to VCU
          signal HVCH_defectHeaterCircuits_oHVCH_Rsp01_oLIN00: start 35, 3 bit, little-endian, i-signal-type=PRIMITIVE, init-value=0, base-type=uint8, compu-method=CM_HVCH_defectHeaterCircuits, data-constr=DC_HVCH_defectHeaterCircuits, to VCU
          signal HVCH_HV_Voltage_Valid_oHVCH_Rsp01_oLIN00: start 40, 2 bit, little-endian, i-signal-type=PRIMITIVE, init-value=0, base-type=uint8, compu-method=CM_HVCH_HV_Voltage_Valid, data-constr=DC_HVCH_HV_Voltage_Valid, to VCU
          signal HVCH_TempSens_Flt_oHVCH_Rsp01_oLIN00: start 42, 1 bit, little-endian, i-signal-type=PRIMITIVE, init-value=0, base-type=boolean, compu-method=CM_HVCH_TempSens_Flt, data-constr=DC_HVCH_TempSens_Flt, to VCU
          signal HVCH_TempLim_oHVCH_Rsp01_oLIN00: start 43, 1 bit, little-endian, i-signal-type=PRIMITIVE, init-value=0, base-type=boolean, compu-method=CM_HVCH_TempLim, data-constr=DC_HVCH_TempLim, to VCU
          signal HVCH_LIN_Flt_oHVCH_Rsp01_oLIN00: start 44, 1 bit, little-endian, i-signal-type=PRIMITIVE, init-value=0, base-type=boolean, compu-method=CM_HVCH_LIN_Flt, data-constr=DC_HVCH_LIN_Flt, to VCU
          signal HVCH_ExtPwrSup_Flt_oHVCH_Rsp01_oLIN00: start 45, 1 bit, little-endian, i-signal-type=PRIMITIVE, init-value=0, base-type=boolean, compu-method=CM_HVCH_ExtPwrSup_Flt, data-constr=DC_HVCH_ExtPwrSup_Flt, to VCU
          signal HVCH_Off_ShrtCurr_oHVCH_Rsp01_oLIN00: start 46, 1 bit, little-endian, i-signal-type=PRIMITIVE, init-value=0, base-type=boolean, compu-method=CM_HVCH_Off_ShrtCurr, data-constr=DC_HVCH_Off_ShrtCurr, to VCU
          signal HVCH_InternalPCBTemp_oHVCH_Rsp01_oLIN00: start 48, 8 bit, little-endian, i-signal-type=PRIMITIVE, init-value=0, base-type=uint8, compu-method=CM_HVCH_InternalPCBTemp, data-constr=DC_HVCH_InternalPCBTemp, to VCU
          signal HVCH_CurrSens_Flt_oHVCH_Rsp01_oLIN00: start 56, 5 bit, little-endian, i-signal-type=PRIMITIVE, init-value=0, base-type=uint8, compu-method=CM_HVCH_CurrSens_Flt, data-constr=DC_HVCH_CurrSens_Flt, to VCU
          signal HVCH_RsErr_oHVCH_Rsp01_oLIN00: start 61, 1 bit, little-endian, i-signal-type=PRIMITIVE, init-value=0, base-type=boolean, compu-method=CM_HVCH_RsErr, data-constr=DC_HVCH_RsErr, to VCU
      frame HVCH_Rsp02_oLIN00: id 0x17, to VCU, frame-length=8, lin-checksum=ENHANCED
        pdu HVCH_Rsp02_oLIN00: length=8, unused-bit-pattern=255
          signal HVCH_IntelTemp_oHVCH_Rsp02_oLIN00: start 0, 8 bit, little-endian, i-signal-type=PRIMITIVE, init-value=0, base-type=uint8, compu-method=CM_HVCH_IntelTemp, data-constr=DC_HVCH_IntelTemp, unit=U_celsius, to VCU
      frame MasterReq_oLIN00: id 0x3C, from VCU, frame-length=8, lin-checksum=CLASSIC
        n pdu MasterReq_Tp_oLIN00: length=8
      frame PMP_Cmd_oLIN00: id 0x24, from VCU, frame-length=8, lin-checksum=ENHANCED
        pdu PMP_Cmd_oLIN00: length=8, unused-bit-pattern=255
          signal ECC_PMP2_SpdSet_oPMP_Cmd_oLIN00: start 8, 8 bit, little-endian, i-signal-type=PRIMITIVE, init-value=0, base-type=uint8, compu-method=CM_ECC_PMP2_SpdSet, data-constr=DC_ECC_PMP2_SpdSet, unit=U_p
          signal ECC_PMP3_SpdSet_oPMP_Cmd_oLIN00: start 16, 8 bit, little-endian, i-signal-type=PRIMITIVE, init-value=0, base-type=uint8, compu-method=CM_ECC_PMP3_SpdSet, data-constr=DC_ECC_PMP3_SpdSet, unit=U_p
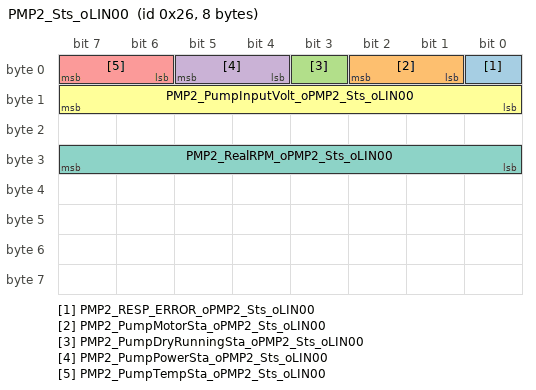
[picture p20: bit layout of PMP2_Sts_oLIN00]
      frame PMP2_Sts_oLIN00: id 0x26, to VCU, frame-length=8, lin-checksum=ENHANCED
        pdu PMP2_Sts_oLIN00: length=8, unused-bit-pattern=255
          signal PMP2_RESP_ERROR_oPMP2_Sts_oLIN00: start 0, 1 bit, little-endian, i-signal-type=PRIMITIVE, init-value=0, base-type=boolean, compu-method=CM_PMP2_RESP_ERROR, data-constr=DC_PMP2_RESP_ERROR, to VCU
          signal PMP2_PumpMotorSta_oPMP2_Sts_oLIN00: start 1, 2 bit, little-endian, i-signal-type=PRIMITIVE, init-value=0, base-type=uint8, compu-method=CM_PMP2_PumpMotorSta, data-constr=DC_PMP2_PumpMotorSta, to VCU
          signal PMP2_PumpDryRunningSta_oPMP2_Sts_oLIN00: start 3, 1 bit, little-endian, i-signal-type=PRIMITIVE, init-value=0, base-type=boolean, compu-method=CM_PMP2_PumpDryRunningSta, data-constr=DC_PMP2_PumpDryRunningSta, to VCU
          signal PMP2_PumpPowerSta_oPMP2_Sts_oLIN00: start 4, 2 bit, little-endian, i-signal-type=PRIMITIVE, init-value=0, base-type=uint8, compu-method=CM_PMP2_PumpPowerSta, data-constr=DC_PMP2_PumpPowerSta, to VCU
          signal PMP2_PumpTempSta_oPMP2_Sts_oLIN00: start 6, 2 bit, little-endian, i-signal-type=PRIMITIVE, init-value=0, base-type=uint8, compu-method=CM_PMP2_PumpTempSta, data-constr=DC_PMP2_PumpTempSta, to VCU
          signal PMP2_PumpInputVolt_oPMP2_Sts_oLIN00: start 8, 8 bit, little-endian, i-signal-type=PRIMITIVE, init-value=0, base-type=uint8, compu-method=CM_PMP2_PumpInputVolt, data-constr=DC_PMP2_PumpInputVolt, unit=U_V, to VCU
          signal PMP2_RealRPM_oPMP2_Sts_oLIN00: start 24, 8 bit, little-endian, i-signal-type=PRIMITIVE, init-value=0, base-type=uint8, compu-method=CM_PMP2_RealRPM, data-constr=DC_PMP2_RealRPM, unit=U_p, to VCU
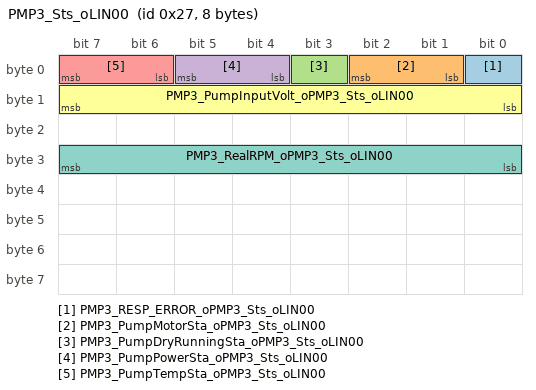
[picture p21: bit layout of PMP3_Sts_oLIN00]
      frame PMP3_Sts_oLIN00: id 0x27, to VCU, frame-length=8, lin-checksum=ENHANCED
        pdu PMP3_Sts_oLIN00: length=8, unused-bit-pattern=255
          signal PMP3_RESP_ERROR_oPMP3_Sts_oLIN00: start 0, 1 bit, little-endian, i-signal-type=PRIMITIVE, init-value=0, base-type=boolean, compu-method=CM_PMP3_RESP_ERROR, data-constr=DC_PMP3_RESP_ERROR, to VCU
          signal PMP3_PumpMotorSta_oPMP3_Sts_oLIN00: start 1, 2 bit, little-endian, i-signal-type=PRIMITIVE, init-value=0, base-type=uint8, compu-method=CM_PMP3_PumpMotorSta, data-constr=DC_PMP3_PumpMotorSta, to VCU
          signal PMP3_PumpDryRunningSta_oPMP3_Sts_oLIN00: start 3, 1 bit, little-endian, i-signal-type=PRIMITIVE, init-value=0, base-type=boolean, compu-method=CM_PMP3_PumpDryRunningSta, data-constr=DC_PMP3_PumpDryRunningSta, to VCU
          signal PMP3_PumpPowerSta_oPMP3_Sts_oLIN00: start 4, 2 bit, little-endian, i-signal-type=PRIMITIVE, init-value=0, base-type=uint8, compu-method=CM_PMP3_PumpPowerSta, data-constr=DC_PMP3_PumpPowerSta, to VCU
          signal PMP3_PumpTempSta_oPMP3_Sts_oLIN00: start 6, 2 bit, little-endian, i-signal-type=PRIMITIVE, init-value=0, base-type=uint8, compu-method=CM_PMP3_PumpTempSta, data-constr=DC_PMP3_PumpTempSta, to VCU
          signal PMP3_PumpInputVolt_oPMP3_Sts_oLIN00: start 8, 8 bit, little-endian, i-signal-type=PRIMITIVE, init-value=0, base-type=uint8, compu-method=CM_PMP3_PumpInputVolt, data-constr=DC_PMP3_PumpInputVolt, unit=U_V, to VCU
          signal PMP3_RealRPM_oPMP3_Sts_oLIN00: start 24, 8 bit, little-endian, i-signal-type=PRIMITIVE, init-value=0, base-type=uint8, compu-method=CM_PMP3_RealRPM, data-constr=DC_PMP3_RealRPM, unit=U_p, to VCU
      frame SlaveResp_oLIN00: id 0x3D, to VCU, frame-length=8, lin-checksum=CLASSIC
        n pdu SlaveResp_Tp_oLIN00: length=8
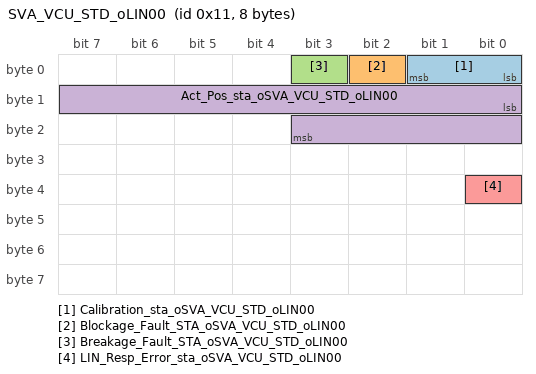
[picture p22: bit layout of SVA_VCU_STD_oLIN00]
      frame SVA_VCU_STD_oLIN00: id 0x11, to VCU, frame-length=8, lin-checksum=ENHANCED
        pdu SVA_VCU_STD_oLIN00: length=8, unused-bit-pattern=255
          signal Calibration_sta_oSVA_VCU_STD_oLIN00: start 0, 2 bit, little-endian, i-signal-type=PRIMITIVE, init-value=0, base-type=uint8, compu-method=CM_Calibration_sta, data-constr=DC_Calibration_sta, to VCU
          signal Blockage_Fault_STA_oSVA_VCU_STD_oLIN00: start 2, 1 bit, little-endian, i-signal-type=PRIMITIVE, init-value=0, base-type=boolean, compu-method=CM_Blockage_Fault_STA, data-constr=DC_Blockage_Fault_STA, to VCU
          signal Breakage_Fault_STA_oSVA_VCU_STD_oLIN00: start 3, 1 bit, little-endian, i-signal-type=PRIMITIVE, init-value=0, base-type=boolean, compu-method=CM_Breakage_Fault_STA, data-constr=DC_Breakage_Fault_STA, to VCU
          signal Act_Pos_sta_oSVA_VCU_STD_oLIN00: start 8, 12 bit, little-endian, i-signal-type=PRIMITIVE, init-value=0, base-type=uint16, compu-method=CM_Act_Pos_sta, data-constr=DC_Act_Pos_sta, unit=U_Degree, to VCU
          signal LIN_Resp_Error_sta_oSVA_VCU_STD_oLIN00: start 32, 1 bit, little-endian, i-signal-type=PRIMITIVE, init-value=0, base-type=boolean, compu-method=CM_LIN_Resp_Error_sta, data-constr=DC_LIN_Resp_Error_sta, to VCU
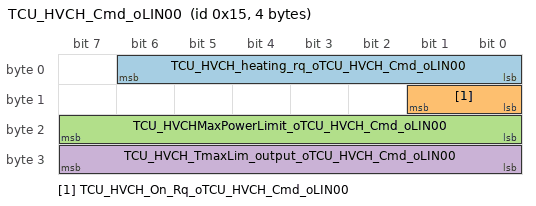
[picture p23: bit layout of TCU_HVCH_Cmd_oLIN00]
      frame TCU_HVCH_Cmd_oLIN00: id 0x15, from VCU, frame-length=4, lin-checksum=ENHANCED
        pdu TCU_HVCH_Cmd_oLIN00: length=4, unused-bit-pattern=255
          signal TCU_HVCH_heating_rq_oTCU_HVCH_Cmd_oLIN00: start 0, 7 bit, little-endian, i-signal-type=PRIMITIVE, init-value=0, base-type=uint8, compu-method=CM_TCU_HVCH_heating_rq, data-constr=DC_TCU_HVCH_heating_rq, unit=U_percent
          signal TCU_HVCH_On_Rq_oTCU_HVCH_Cmd_oLIN00: start 8, 2 bit, little-endian, i-signal-type=PRIMITIVE, init-value=0, base-type=uint8, invalid-value=3, compu-method=CM_TCU_HVCH_On_Rq, data-constr=DC_TCU_HVCH_On_Rq
          signal TCU_HVCHMaxPowerLimit_oTCU_HVCH_Cmd_oLIN00: start 16, 8 bit, little-endian, i-signal-type=PRIMITIVE, init-value=0, base-type=uint8, compu-method=CM_TCU_HVCHMaxPowerLimit, data-constr=DC_TCU_HVCHMaxPowerLimit, unit=U_KW
          signal TCU_HVCH_TmaxLim_output_oTCU_HVCH_Cmd_oLIN00: start 24, 8 bit, little-endian, i-signal-type=PRIMITIVE, init-value=0, base-type=uint8, compu-method=CM_TCU_HVCH_TmaxLim_output, data-constr=DC_TCU_HVCH_TmaxLim_output, unit=U_celsius
      frame VCU_EXV_1_oLIN00: id 0x1F, from VCU, frame-length=8, lin-checksum=ENHANCED
        pdu VCU_EXV_1_oLIN00: length=8, unused-bit-pattern=255
          signal TMM_EXV1_PositionRequest_oVCU_EXV_1_oLIN00: start 0, 16 bit, little-endian, i-signal-type=PRIMITIVE, init-value=0, base-type=uint16, compu-method=CM_TMM_EXV1_PositionRequest, data-constr=DC_TMM_EXV1_PositionRequest
          signal TMM_EXV1_EnableRequest_oVCU_EXV_1_oLIN00: start 16, 1 bit, little-endian, i-signal-type=PRIMITIVE, init-value=0, base-type=boolean, compu-method=CM_TMM_EXV1_EnableRequest, data-constr=DC_TMM_EXV1_EnableRequest
          signal TMM_EXV1_initRequest_oVCU_EXV_1_oLIN00: start 24, 3 bit, little-endian, i-signal-type=PRIMITIVE, init-value=0, base-type=uint8, compu-method=CM_TMM_EXV1_initRequest, data-constr=DC_TMM_EXV1_initRequest
      frame VCU_EXV_2_oLIN00: id 0x34, from VCU, frame-length=8, lin-checksum=ENHANCED
        pdu VCU_EXV_2_oLIN00: length=8, unused-bit-pattern=255
          signal TMM_EXV2_PositionRequest_oVCU_EXV_2_oLIN00: start 0, 16 bit, little-endian, i-signal-type=PRIMITIVE, init-value=0, base-type=uint16, compu-method=CM_TMM_EXV2_PositionRequest, data-constr=DC_TMM_EXV2_PositionRequest
          signal TMM_EXV2_EnableRequest_oVCU_EXV_2_oLIN00: start 16, 1 bit, little-endian, i-signal-type=PRIMITIVE, init-value=0, base-type=boolean, compu-method=CM_TMM_EXV2_EnableRequest, data-constr=DC_TMM_EXV2_EnableRequest
          signal TMM_EXV2_initRequest_oVCU_EXV_2_oLIN00: start 24, 3 bit, little-endian, i-signal-type=PRIMITIVE, init-value=0, base-type=uint8, compu-method=CM_TMM_EXV2_initRequest, data-constr=DC_TMM_EXV2_initRequest
      frame VCU_SVA_CMD_oLIN00: id 0x10, from VCU, frame-length=8, lin-checksum=ENHANCED
        pdu VCU_SVA_CMD_oLIN00: length=8, unused-bit-pattern=255
          signal Calibration_cmd_oVCU_SVA_CMD_oLIN00: start 8, 1 bit, little-endian, i-signal-type=PRIMITIVE, init-value=0, base-type=boolean, compu-method=CM_Calibration_cmd, data-constr=DC_Calibration_cmd
          signal Target_Pos_cmd_oVCU_SVA_CMD_oLIN00: start 16, 12 bit, little-endian, i-signal-type=PRIMITIVE, init-value=0, base-type=uint16, compu-method=CM_Target_Pos_cmd, data-constr=DC_Target_Pos_cmd, unit=U_Degree
      pdu triggering PT_MasterReq: pdu=MasterReq_oLIN00, from VCU
      pdu triggering PT_MasterReq_ERV: pdu=MasterReq_ERV_oLIN00, from VCU
      pdu triggering PT_MasterReq_EXV_1: pdu=MasterReq_EXV_1_oLIN00, from VCU
      pdu triggering PT_MasterReq_EXV_2: pdu=MasterReq_EXV_2_oLIN00, from VCU
      pdu triggering PT_MasterReq_HVCH: pdu=MasterReq_HVCH_oLIN00, from VCU
      pdu triggering PT_MasterReq_PMP_1: pdu=MasterReq_PMP_1_oLIN00, from VCU
      pdu triggering PT_MasterReq_PMP_2: pdu=MasterReq_PMP_2_oLIN00, from VCU
      pdu triggering PT_MasterReq_SVA: pdu=MasterReq_SVA_oLIN00, from VCU
      pdu triggering PT_SlaveResp_ERV: pdu=SlaveResp_ERV_oLIN00, to VCU
      pdu triggering PT_SlaveResp_EXV_1: pdu=SlaveResp_EXV_1_oLIN00, to VCU
      pdu triggering PT_SlaveResp_EXV_2: pdu=SlaveResp_EXV_2_oLIN00, to VCU
      pdu triggering PT_SlaveResp_HVCH: pdu=SlaveResp_HVCH_oLIN00, to VCU
      pdu triggering PT_SlaveResp_PMP_1: pdu=SlaveResp_PMP_1_oLIN00, to VCU
      pdu triggering PT_SlaveResp_PMP_2: pdu=SlaveResp_PMP_2_oLIN00, to VCU
      pdu triggering PT_SlaveResp_SVA: pdu=SlaveResp_SVA_oLIN00, to VCU
      lin schedule table TCU_LIN_Schedule: run-mode=RUN-CONTINUOUS
        table-entrys:
          delay=0.01, position-in-table=0, frame-triggering=FT_EDCU_EXV2
          delay=0.01, position-in-table=1, frame-triggering=FT_EXV2_Status
          delay=0.1, position-in-table=2, frame-triggering=FT_VCU_EXV_1
          delay=0.1, position-in-table=3, frame-triggering=FT_EXV_1_VCU
          delay=0.1, position-in-table=4, frame-triggering=FT_VCU_EXV_2
          delay=0.1, position-in-table=5, frame-triggering=FT_EXV_2_VCU
          delay=0.01, position-in-table=6, frame-triggering=FT_PMP_Cmd
          delay=0.01, position-in-table=7, frame-triggering=FT_PMP2_Sts
          delay=0.01, position-in-table=8, frame-triggering=FT_PMP3_Sts
          delay=0.015, position-in-table=9, frame-triggering=FT_VCU_SVA_CMD
          delay=0.015, position-in-table=10, frame-triggering=FT_SVA_VCU_STD
          delay=0.02, position-in-table=11, frame-triggering=FT_TCU_HVCH_Cmd
          delay=0.02, position-in-table=12, frame-triggering=FT_HVCH_Rsp01
          delay=0.02, position-in-table=13, frame-triggering=FT_HVCH_Rsp02
package /ECU
  ecu instance VCU: associated-com-i-pdu-group=[VCU_oKAMA_FP_EPT_0303_Rx, VCU_oKAMA_FP_EPT_0303_Tx, VCU_oLIN00_Rx, VCU_oLIN00_Tx, VCU_oTC37X_VCU_CAN00_Rx, VCU_oTC37X_VCU_CAN00_Tx, VCU_oTC37X_VCU_CAN01_Rx, VCU_oTC37X_VCU_CAN01_Tx, VCU_oTC37X_VCU_CAN03_Rx, VCU_oTC37X_VCU_CAN03_Tx]
    4 x can communication controller:
      CT_KAMA_FP_EPT_0303
      CT_TC37X_VCU_CAN00
      CT_TC37X_VCU_CAN01
      CT_TC37X_VCU_CAN03
    lin master CT_LIN00: protocol-version=LIN21, time-base=0.005, time-base-jitter=0.0001
    can communication connector CN_KAMA_FP_EPT_0303: comm-controller=CT_KAMA_FP_EPT_0303
    can communication connector CN_TC37X_VCU_CAN00: comm-controller=CT_TC37X_VCU_CAN00
    can communication connector CN_TC37X_VCU_CAN01: comm-controller=CT_TC37X_VCU_CAN01
    can communication connector CN_TC37X_VCU_CAN03: comm-controller=CT_TC37X_VCU_CAN03
    lin communication connector CN_LIN00: comm-controller=CT_LIN00
package /Gateway
  gateway VCU: ecu=VCU
package /IPDUGroup
  10 x i signal i pdu group:
    VCU_oKAMA_FP_EPT_0303_Rx: communication-direction=IN, i-signal-i-pdus=VCU_Minor_03_oKAMA_FP_EPT_0303
    VCU_oKAMA_FP_EPT_0303_Tx: communication-direction=OUT, i-signal-i-pdus=[VCU_Minor_01_oKAMA_FP_EPT_0303, VCU_Minor_02_oKAMA_FP_EPT_0303]
    VCU_oLIN00_Rx: communication-direction=IN
      i-signal-i-pdus:
        EXV_1_VCU_oLIN00
        EXV_2_VCU_oLIN00
        EXV2_Status_oLIN00
        HVCH_Rsp01_oLIN00
        HVCH_Rsp02_oLIN00
        PMP2_Sts_oLIN00
        PMP3_Sts_oLIN00
        SVA_VCU_STD_oLIN00
    VCU_oLIN00_Tx: communication-direction=OUT, i-signal-i-pdus=[EDCU_EXV2_oLIN00, PMP_Cmd_oLIN00, TCU_HVCH_Cmd_oLIN00, VCU_EXV_1_oLIN00, VCU_EXV_2_oLIN00, VCU_SVA_CMD_oLIN00]
    VCU_oTC37X_VCU_CAN00_Rx: communication-direction=IN, i-signal-i-pdus=[VcuRxMsg1_oTC37X_VCU_CAN00, VcuRxMsg2_oTC37X_VCU_CAN00]
    VCU_oTC37X_VCU_CAN00_Tx: communication-direction=OUT
      i-signal-i-pdus:
        VcuTxIoMsg{1..8}_oTC37X_VCU_CAN00
        VcuTxMsg1_oTC37X_VCU_CAN00
        VcuTxMsg2_oTC37X_VCU_CAN00
    VCU_oTC37X_VCU_CAN01_Rx: communication-direction=IN, i-signal-i-pdus=[IBS_Status_06_oTC37X_VCU_CAN01, VcuRxMsg3_oTC37X_VCU_CAN01, VcuRxMsg4_oTC37X_VCU_CAN01]
    VCU_oTC37X_VCU_CAN01_Tx: communication-direction=OUT, i-signal-i-pdus=[VCU_BMS_oTC37X_VCU_CAN01, VcuAdcTxMsg1_oTC37X_VCU_CAN01, VcuAdcTxMsg2_oTC37X_VCU_CAN01]
    VCU_oTC37X_VCU_CAN03_Rx: communication-direction=IN, i-signal-i-pdus=[VcuCan03RxMsg1_oTC37X_VCU_CAN03, VcuCan03RxMsg2_oTC37X_VCU_CAN03]
    VCU_oTC37X_VCU_CAN03_Tx: communication-direction=OUT, i-signal-i-pdus=[VcuCan03TxMsg1_oTC37X_VCU_CAN03, VcuCan03TxMsg2_oTC37X_VCU_CAN03]
package /PDU
  dcm i pdu MasterReq_ERV_oLIN00: length=8, diag-pdu-type=DIAG-REQUEST
  dcm i pdu MasterReq_EXV_1_oLIN00: length=8, diag-pdu-type=DIAG-REQUEST
  dcm i pdu MasterReq_EXV_2_oLIN00: length=8, diag-pdu-type=DIAG-REQUEST
  dcm i pdu MasterReq_HVCH_oLIN00: length=8, diag-pdu-type=DIAG-REQUEST
  dcm i pdu MasterReq_oLIN00: length=8, diag-pdu-type=DIAG-REQUEST
  dcm i pdu MasterReq_PMP_1_oLIN00: length=8, diag-pdu-type=DIAG-REQUEST
  dcm i pdu MasterReq_PMP_2_oLIN00: length=8, diag-pdu-type=DIAG-REQUEST
  dcm i pdu MasterReq_SVA_oLIN00: length=8, diag-pdu-type=DIAG-REQUEST
  dcm i pdu SlaveResp_ERV_oLIN00: length=8, diag-pdu-type=DIAG-RESPONSE
  dcm i pdu SlaveResp_EXV_1_oLIN00: length=8, diag-pdu-type=DIAG-RESPONSE
  dcm i pdu SlaveResp_EXV_2_oLIN00: length=8, diag-pdu-type=DIAG-RESPONSE
  dcm i pdu SlaveResp_HVCH_oLIN00: length=8, diag-pdu-type=DIAG-RESPONSE
  dcm i pdu SlaveResp_PMP_1_oLIN00: length=8, diag-pdu-type=DIAG-RESPONSE
  dcm i pdu SlaveResp_PMP_2_oLIN00: length=8, diag-pdu-type=DIAG-RESPONSE
  dcm i pdu SlaveResp_SVA_oLIN00: length=8, diag-pdu-type=DIAG-RESPONSE
  dcm i pdu Vcu_Uds_Func_Request_oTC37X_VCU_CAN00: length=7, diag-pdu-type=DIAG-REQUEST
  dcm i pdu Vcu_Uds_Phy_Request_oTC37X_VCU_CAN00: length=8, diag-pdu-type=DIAG-REQUEST
  dcm i pdu Vcu_Uds_Response_oTC37X_VCU_CAN00: length=8, diag-pdu-type=DIAG-RESPONSE
package /ISignal
  i signal group SG_IBS_Status_06_Signal_Group_oIBS_Status_06_oTC37X_VCU_CAN01: i-signal=[Checksum_0BC_oIBS_Status_06_oTC37X_VCU_CAN01, IBS_AVHSts_oIBS_Status_06_oTC37X_VCU_CAN01, IBS_BrakeFluidWarning_oIBS_Status_06_oTC37X_VCU_CAN01, IBS_EPBFailureStatus_oIBS_Status_06_oTC37X_VCU_CAN01, IBS_ESClampdisplay_oIBS_Status_06_oTC37X_VCU_CAN01, IBS_ESCOffSts_oIBS_Status_06_oTC37X_VCU_CAN01, IBS_FactoryMode_oIBS_Status_06_oTC37X_VCU_CAN01, IBS_HBAActive_oIBS_Status_06_oTC37X_VCU_CAN01, IBS_HDCSts_oIBS_Status_06_oTC37X_VCU_CAN01, IBS_MaintenaceMode_oIBS_Status_06_oTC37X_VCU_CAN01, IBS_RollerbenchMode_oIBS_Status_06_oTC37X_VCU_CAN01, IBS_RWUActive_oIBS_Status_06_oTC37X_VCU_CAN01, IBS_RWUAvailable_oIBS_Status_06_oTC37X_VCU_CAN01, IBS_TireMonSysSts_oIBS_Status_06_oTC37X_VCU_CAN01, IBS_TireWarnFrntLe_oIBS_Status_06_oTC37X_VCU_CAN01, IBS_TireWarnFrntRi_oIBS_Status_06_oTC37X_VCU_CAN01, IBS_TireWarnReLe_oIBS_Status_06_oTC37X_VCU_CAN01, IBS_TireWarnReRi_oIBS_Status_06_oTC37X_VCU_CAN01, IBS_TPMS_ResetSts_oIBS_Status_06_oTC37X_VCU_CAN01, MessageCounter_0BC_oIBS_Status_06_oTC37X_VCU_CAN01], system-signal-group=SG_IBS_Status_06_Signal_Group
  i signal group SG_VCU_BMS_Signal_Group_oVCU_BMS_oTC37X_VCU_CAN01: i-signal=[Checksum_0D1_oVCU_BMS_oTC37X_VCU_CAN01, MessageCounter_0D1_oVCU_BMS_oTC37X_VCU_CAN01, VCU_ActDriveMode_oVCU_BMS_oTC37X_VCU_CAN01, VCU_ActiveEnergyProfile_oVCU_BMS_oTC37X_VCU_CAN01, VCU_ActiveRgnBrkProfile_oVCU_BMS_oTC37X_VCU_CAN01, VCU_BMS_Control_of_NegRelay_oVCU_BMS_oTC37X_VCU_CAN01, VCU_BMSTargetThermLevel_oVCU_BMS_oTC37X_VCU_CAN01, VCU_Chargestatus_oVCU_BMS_oTC37X_VCU_CAN01, VCU_DrvModSwitchWarn_oVCU_BMS_oTC37X_VCU_CAN01, VCU_HVStatus_oVCU_BMS_oTC37X_VCU_CAN01, VCU_IsomeasurmentSwitch_oVCU_BMS_oTC37X_VCU_CAN01, VCU_LimitLevel_oVCU_BMS_oTC37X_VCU_CAN01, VCU_RegenBrakeLightRequest_oVCU_BMS_oTC37X_VCU_CAN01, VCU_RegenBrakeLightReqVld_oVCU_BMS_oTC37X_VCU_CAN01, VCU_RequestedModeBMS_oVCU_BMS_oTC37X_VCU_CAN01], system-signal-group=SG_VCU_BMS_Signal_Group
